[part 1 of 5: package /IBNvBlkSWC_4]
AUTOSAR XML (schema 00050)
package /IBNvBlkSWC_4
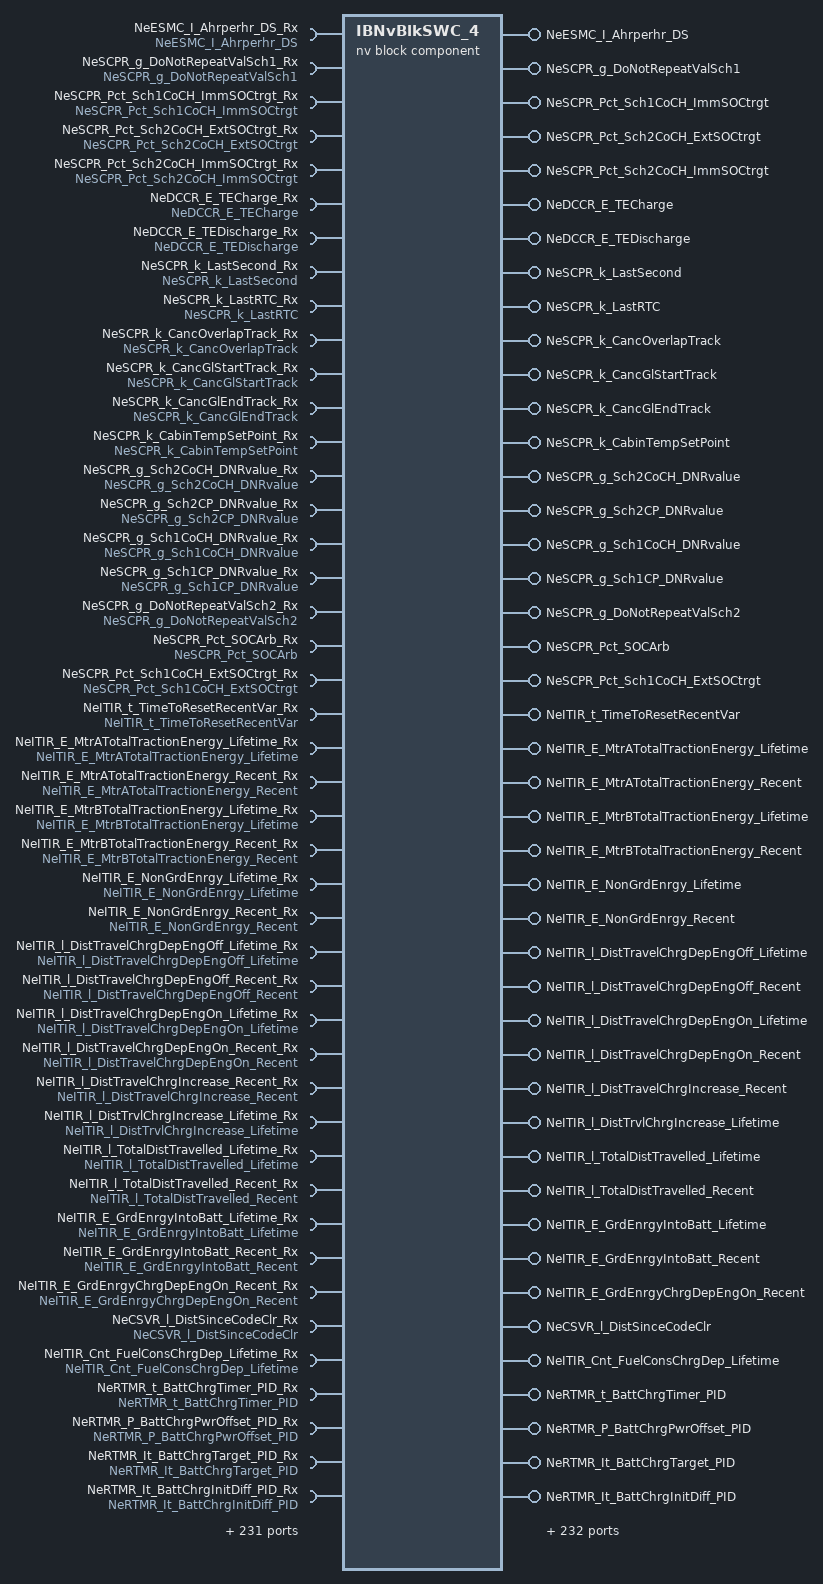
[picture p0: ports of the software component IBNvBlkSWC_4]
  nv block sw component type IBNvBlkSWC_4
    provide port NeESMC_I_Ahrperhr_DS: nv-provide-com-spec{ram-block-init-value=Value:0, rom-block-init-value=Value:0, variable=NeESMC_I_Ahrperhr_DS}, provided-interface=NeESMC_I_Ahrperhr_DS
    require port NeESMC_I_Ahrperhr_DS_Rx: nv-require-com-spec{init-value=Value:0, variable=NeESMC_I_Ahrperhr_DS}, required-interface=NeESMC_I_Ahrperhr_DS
    provide port NeSCPR_g_DoNotRepeatValSch1: nv-provide-com-spec{ram-block-init-value=Value:0, rom-block-init-value=Value:0, variable=NeSCPR_g_DoNotRepeatValSch1}, provided-interface=NeSCPR_g_DoNotRepeatValSch1
    require port NeSCPR_g_DoNotRepeatValSch1_Rx: nv-require-com-spec{init-value=Value:0, variable=NeSCPR_g_DoNotRepeatValSch1}, required-interface=NeSCPR_g_DoNotRepeatValSch1
    provide port NeSCPR_Pct_Sch1CoCH_ImmSOCtrgt: nv-provide-com-spec{ram-block-init-value=Value:0, rom-block-init-value=Value:0, variable=NeSCPR_Pct_Sch1CoCH_ImmSOCtrgt}, provided-interface=NeSCPR_Pct_Sch1CoCH_ImmSOCtrgt
    require port NeSCPR_Pct_Sch1CoCH_ImmSOCtrgt_Rx: nv-require-com-spec{init-value=Value:0, variable=NeSCPR_Pct_Sch1CoCH_ImmSOCtrgt}, required-interface=NeSCPR_Pct_Sch1CoCH_ImmSOCtrgt
    provide port NeSCPR_Pct_Sch2CoCH_ExtSOCtrgt: nv-provide-com-spec{ram-block-init-value=Value:0, rom-block-init-value=Value:0, variable=NeSCPR_Pct_Sch2CoCH_ExtSOCtrgt}, provided-interface=NeSCPR_Pct_Sch2CoCH_ExtSOCtrgt
    require port NeSCPR_Pct_Sch2CoCH_ExtSOCtrgt_Rx: nv-require-com-spec{init-value=Value:0, variable=NeSCPR_Pct_Sch2CoCH_ExtSOCtrgt}, required-interface=NeSCPR_Pct_Sch2CoCH_ExtSOCtrgt
    provide port NeSCPR_Pct_Sch2CoCH_ImmSOCtrgt: nv-provide-com-spec{ram-block-init-value=Value:0, rom-block-init-value=Value:0, variable=NeSCPR_Pct_Sch2CoCH_ImmSOCtrgt}, provided-interface=NeSCPR_Pct_Sch2CoCH_ImmSOCtrgt
    require port NeSCPR_Pct_Sch2CoCH_ImmSOCtrgt_Rx: nv-require-com-spec{init-value=Value:0, variable=NeSCPR_Pct_Sch2CoCH_ImmSOCtrgt}, required-interface=NeSCPR_Pct_Sch2CoCH_ImmSOCtrgt
    provide port NeDCCR_E_TECharge: nv-provide-com-spec{ram-block-init-value=Value:0, rom-block-init-value=Value:0, variable=NeDCCR_E_TECharge}, provided-interface=NeDCCR_E_TECharge
    require port NeDCCR_E_TECharge_Rx: nv-require-com-spec{init-value=Value:0, variable=NeDCCR_E_TECharge}, required-interface=NeDCCR_E_TECharge
    provide port NeDCCR_E_TEDischarge: nv-provide-com-spec{ram-block-init-value=Value:0, rom-block-init-value=Value:0, variable=NeDCCR_E_TEDischarge}, provided-interface=NeDCCR_E_TEDischarge
    require port NeDCCR_E_TEDischarge_Rx: nv-require-com-spec{init-value=Value:0, variable=NeDCCR_E_TEDischarge}, required-interface=NeDCCR_E_TEDischarge
    provide port NeSCPR_k_LastSecond: nv-provide-com-spec{ram-block-init-value=Value:0, rom-block-init-value=Value:0, variable=NeSCPR_k_LastSecond}, provided-interface=NeSCPR_k_LastSecond
    require port NeSCPR_k_LastSecond_Rx: nv-require-com-spec{init-value=Value:0, variable=NeSCPR_k_LastSecond}, required-interface=NeSCPR_k_LastSecond
    provide port NeSCPR_k_LastRTC: nv-provide-com-spec{ram-block-init-value=Value:0, rom-block-init-value=Value:0, variable=NeSCPR_k_LastRTC}, provided-interface=NeSCPR_k_LastRTC
    require port NeSCPR_k_LastRTC_Rx: nv-require-com-spec{init-value=Value:0, variable=NeSCPR_k_LastRTC}, required-interface=NeSCPR_k_LastRTC
    provide port NeSCPR_k_CancOverlapTrack: nv-provide-com-spec{ram-block-init-value=Value:0, rom-block-init-value=Value:0, variable=NeSCPR_k_CancOverlapTrack}, provided-interface=NeSCPR_k_CancOverlapTrack
    require port NeSCPR_k_CancOverlapTrack_Rx: nv-require-com-spec{init-value=Value:0, variable=NeSCPR_k_CancOverlapTrack}, required-interface=NeSCPR_k_CancOverlapTrack
    provide port NeSCPR_k_CancGlStartTrack: nv-provide-com-spec{ram-block-init-value=Value:0, rom-block-init-value=Value:0, variable=NeSCPR_k_CancGlStartTrack}, provided-interface=NeSCPR_k_CancGlStartTrack
    require port NeSCPR_k_CancGlStartTrack_Rx: nv-require-com-spec{init-value=Value:0, variable=NeSCPR_k_CancGlStartTrack}, required-interface=NeSCPR_k_CancGlStartTrack
    provide port NeSCPR_k_CancGlEndTrack: nv-provide-com-spec{ram-block-init-value=Value:0, rom-block-init-value=Value:0, variable=NeSCPR_k_CancGlEndTrack}, provided-interface=NeSCPR_k_CancGlEndTrack
    require port NeSCPR_k_CancGlEndTrack_Rx: nv-require-com-spec{init-value=Value:0, variable=NeSCPR_k_CancGlEndTrack}, required-interface=NeSCPR_k_CancGlEndTrack
    provide port NeSCPR_k_CabinTempSetPoint: nv-provide-com-spec{ram-block-init-value=Value:4294967295, rom-block-init-value=Value:4294967295, variable=NeSCPR_k_CabinTempSetPoint}, provided-interface=NeSCPR_k_CabinTempSetPoint
    require port NeSCPR_k_CabinTempSetPoint_Rx: nv-require-com-spec{init-value=Value:4294967295, variable=NeSCPR_k_CabinTempSetPoint}, required-interface=NeSCPR_k_CabinTempSetPoint
    provide port NeSCPR_g_Sch2CoCH_DNRvalue: nv-provide-com-spec{ram-block-init-value=Value:0, rom-block-init-value=Value:0, variable=NeSCPR_g_Sch2CoCH_DNRvalue}, provided-interface=NeSCPR_g_Sch2CoCH_DNRvalue
    require port NeSCPR_g_Sch2CoCH_DNRvalue_Rx: nv-require-com-spec{init-value=Value:0, variable=NeSCPR_g_Sch2CoCH_DNRvalue}, required-interface=NeSCPR_g_Sch2CoCH_DNRvalue
    provide port NeSCPR_g_Sch2CP_DNRvalue: nv-provide-com-spec{ram-block-init-value=Value:0, rom-block-init-value=Value:0, variable=NeSCPR_g_Sch2CP_DNRvalue}, provided-interface=NeSCPR_g_Sch2CP_DNRvalue
    require port NeSCPR_g_Sch2CP_DNRvalue_Rx: nv-require-com-spec{init-value=Value:0, variable=NeSCPR_g_Sch2CP_DNRvalue}, required-interface=NeSCPR_g_Sch2CP_DNRvalue
    provide port NeSCPR_g_Sch1CoCH_DNRvalue: nv-provide-com-spec{ram-block-init-value=Value:0, rom-block-init-value=Value:0, variable=NeSCPR_g_Sch1CoCH_DNRvalue}, provided-interface=NeSCPR_g_Sch1CoCH_DNRvalue
    require port NeSCPR_g_Sch1CoCH_DNRvalue_Rx: nv-require-com-spec{init-value=Value:0, variable=NeSCPR_g_Sch1CoCH_DNRvalue}, required-interface=NeSCPR_g_Sch1CoCH_DNRvalue
    provide port NeSCPR_g_Sch1CP_DNRvalue: nv-provide-com-spec{ram-block-init-value=Value:0, rom-block-init-value=Value:0, variable=NeSCPR_g_Sch1CP_DNRvalue}, provided-interface=NeSCPR_g_Sch1CP_DNRvalue
    require port NeSCPR_g_Sch1CP_DNRvalue_Rx: nv-require-com-spec{init-value=Value:0, variable=NeSCPR_g_Sch1CP_DNRvalue}, required-interface=NeSCPR_g_Sch1CP_DNRvalue
    provide port NeSCPR_g_DoNotRepeatValSch2: nv-provide-com-spec{ram-block-init-value=Value:0, rom-block-init-value=Value:0, variable=NeSCPR_g_DoNotRepeatValSch2}, provided-interface=NeSCPR_g_DoNotRepeatValSch2
    require port NeSCPR_g_DoNotRepeatValSch2_Rx: nv-require-com-spec{init-value=Value:0, variable=NeSCPR_g_DoNotRepeatValSch2}, required-interface=NeSCPR_g_DoNotRepeatValSch2
    provide port NeSCPR_Pct_SOCArb: nv-provide-com-spec{ram-block-init-value=Value:100, rom-block-init-value=Value:100, variable=NeSCPR_Pct_SOCArb}, provided-interface=NeSCPR_Pct_SOCArb
    require port NeSCPR_Pct_SOCArb_Rx: nv-require-com-spec{init-value=Value:100, variable=NeSCPR_Pct_SOCArb}, required-interface=NeSCPR_Pct_SOCArb
    provide port NeSCPR_Pct_Sch1CoCH_ExtSOCtrgt: nv-provide-com-spec{ram-block-init-value=Value:0, rom-block-init-value=Value:0, variable=NeSCPR_Pct_Sch1CoCH_ExtSOCtrgt}, provided-interface=NeSCPR_Pct_Sch1CoCH_ExtSOCtrgt
    require port NeSCPR_Pct_Sch1CoCH_ExtSOCtrgt_Rx: nv-require-com-spec{init-value=Value:0, variable=NeSCPR_Pct_Sch1CoCH_ExtSOCtrgt}, required-interface=NeSCPR_Pct_Sch1CoCH_ExtSOCtrgt
    provide port NeITIR_t_TimeToResetRecentVar: nv-provide-com-spec{ram-block-init-value=Value:0, rom-block-init-value=Value:0, variable=NeITIR_t_TimeToResetRecentVar}, provided-interface=NeITIR_t_TimeToResetRecentVar
    require port NeITIR_t_TimeToResetRecentVar_Rx: nv-require-com-spec{init-value=Value:0, variable=NeITIR_t_TimeToResetRecentVar}, required-interface=NeITIR_t_TimeToResetRecentVar
    provide port NeITIR_E_MtrATotalTractionEnergy_Lifetime: nv-provide-com-spec{ram-block-init-value=Value:0, rom-block-init-value=Value:0, variable=NeITIR_E_MtrATotalTractionEnergy_Lifetime}, provided-interface=NeITIR_E_MtrATotalTractionEnergy_Lifetime
    require port NeITIR_E_MtrATotalTractionEnergy_Lifetime_Rx: nv-require-com-spec{init-value=Value:0, variable=NeITIR_E_MtrATotalTractionEnergy_Lifetime}, required-interface=NeITIR_E_MtrATotalTractionEnergy_Lifetime
    provide port NeITIR_E_MtrATotalTractionEnergy_Recent: nv-provide-com-spec{ram-block-init-value=Value:0, rom-block-init-value=Value:0, variable=NeITIR_E_MtrATotalTractionEnergy_Recent}, provided-interface=NeITIR_E_MtrATotalTractionEnergy_Recent
    require port NeITIR_E_MtrATotalTractionEnergy_Recent_Rx: nv-require-com-spec{init-value=Value:0, variable=NeITIR_E_MtrATotalTractionEnergy_Recent}, required-interface=NeITIR_E_MtrATotalTractionEnergy_Recent
    provide port NeITIR_E_MtrBTotalTractionEnergy_Lifetime: nv-provide-com-spec{ram-block-init-value=Value:0, rom-block-init-value=Value:0, variable=NeITIR_E_MtrBTotalTractionEnergy_Lifetime}, provided-interface=NeITIR_E_MtrBTotalTractionEnergy_Lifetime
    require port NeITIR_E_MtrBTotalTractionEnergy_Lifetime_Rx: nv-require-com-spec{init-value=Value:0, variable=NeITIR_E_MtrBTotalTractionEnergy_Lifetime}, required-interface=NeITIR_E_MtrBTotalTractionEnergy_Lifetime
    provide port NeITIR_E_MtrBTotalTractionEnergy_Recent: nv-provide-com-spec{ram-block-init-value=Value:0, rom-block-init-value=Value:0, variable=NeITIR_E_MtrBTotalTractionEnergy_Recent}, provided-interface=NeITIR_E_MtrBTotalTractionEnergy_Recent
    require port NeITIR_E_MtrBTotalTractionEnergy_Recent_Rx: nv-require-com-spec{init-value=Value:0, variable=NeITIR_E_MtrBTotalTractionEnergy_Recent}, required-interface=NeITIR_E_MtrBTotalTractionEnergy_Recent
    provide port NeITIR_E_NonGrdEnrgy_Lifetime: nv-provide-com-spec{ram-block-init-value=Value:0, rom-block-init-value=Value:0, variable=NeITIR_E_NonGrdEnrgy_Lifetime}, provided-interface=NeITIR_E_NonGrdEnrgy_Lifetime
    require port NeITIR_E_NonGrdEnrgy_Lifetime_Rx: nv-require-com-spec{init-value=Value:0, variable=NeITIR_E_NonGrdEnrgy_Lifetime}, required-interface=NeITIR_E_NonGrdEnrgy_Lifetime
    provide port NeITIR_E_NonGrdEnrgy_Recent: nv-provide-com-spec{ram-block-init-value=Value:0, rom-block-init-value=Value:0, variable=NeITIR_E_NonGrdEnrgy_Recent}, provided-interface=NeITIR_E_NonGrdEnrgy_Recent
    require port NeITIR_E_NonGrdEnrgy_Recent_Rx: nv-require-com-spec{init-value=Value:0, variable=NeITIR_E_NonGrdEnrgy_Recent}, required-interface=NeITIR_E_NonGrdEnrgy_Recent
    provide port NeITIR_l_DistTravelChrgDepEngOff_Lifetime: nv-provide-com-spec{ram-block-init-value=Value:0, rom-block-init-value=Value:0, variable=NeITIR_l_DistTravelChrgDepEngOff_Lifetime}, provided-interface=NeITIR_l_DistTravelChrgDepEngOff_Lifetime
    require port NeITIR_l_DistTravelChrgDepEngOff_Lifetime_Rx: nv-require-com-spec{init-value=Value:0, variable=NeITIR_l_DistTravelChrgDepEngOff_Lifetime}, required-interface=NeITIR_l_DistTravelChrgDepEngOff_Lifetime
    provide port NeITIR_l_DistTravelChrgDepEngOff_Recent: nv-provide-com-spec{ram-block-init-value=Value:0, rom-block-init-value=Value:0, variable=NeITIR_l_DistTravelChrgDepEngOff_Recent}, provided-interface=NeITIR_l_DistTravelChrgDepEngOff_Recent
    require port NeITIR_l_DistTravelChrgDepEngOff_Recent_Rx: nv-require-com-spec{init-value=Value:0, variable=NeITIR_l_DistTravelChrgDepEngOff_Recent}, required-interface=NeITIR_l_DistTravelChrgDepEngOff_Recent
    provide port NeITIR_l_DistTravelChrgDepEngOn_Lifetime: nv-provide-com-spec{ram-block-init-value=Value:0, rom-block-init-value=Value:0, variable=NeITIR_l_DistTravelChrgDepEngOn_Lifetime}, provided-interface=NeITIR_l_DistTravelChrgDepEngOn_Lifetime
    require port NeITIR_l_DistTravelChrgDepEngOn_Lifetime_Rx: nv-require-com-spec{init-value=Value:0, variable=NeITIR_l_DistTravelChrgDepEngOn_Lifetime}, required-interface=NeITIR_l_DistTravelChrgDepEngOn_Lifetime
    provide port NeITIR_l_DistTravelChrgDepEngOn_Recent: nv-provide-com-spec{ram-block-init-value=Value:0, rom-block-init-value=Value:0, variable=NeITIR_l_DistTravelChrgDepEngOn_Recent}, provided-interface=NeITIR_l_DistTravelChrgDepEngOn_Recent
    require port NeITIR_l_DistTravelChrgDepEngOn_Recent_Rx: nv-require-com-spec{init-value=Value:0, variable=NeITIR_l_DistTravelChrgDepEngOn_Recent}, required-interface=NeITIR_l_DistTravelChrgDepEngOn_Recent
    provide port NeITIR_l_DistTravelChrgIncrease_Recent: nv-provide-com-spec{ram-block-init-value=Value:0, rom-block-init-value=Value:0, variable=NeITIR_l_DistTravelChrgIncrease_Recent}, provided-interface=NeITIR_l_DistTravelChrgIncrease_Recent
    require port NeITIR_l_DistTravelChrgIncrease_Recent_Rx: nv-require-com-spec{init-value=Value:0, variable=NeITIR_l_DistTravelChrgIncrease_Recent}, required-interface=NeITIR_l_DistTravelChrgIncrease_Recent
    provide port NeITIR_l_DistTrvlChrgIncrease_Lifetime: nv-provide-com-spec{ram-block-init-value=Value:0, rom-block-init-value=Value:0, variable=NeITIR_l_DistTrvlChrgIncrease_Lifetime}, provided-interface=NeITIR_l_DistTrvlChrgIncrease_Lifetime
    require port NeITIR_l_DistTrvlChrgIncrease_Lifetime_Rx: nv-require-com-spec{init-value=Value:0, variable=NeITIR_l_DistTrvlChrgIncrease_Lifetime}, required-interface=NeITIR_l_DistTrvlChrgIncrease_Lifetime
    provide port NeITIR_l_TotalDistTravelled_Lifetime: nv-provide-com-spec{ram-block-init-value=Value:0, rom-block-init-value=Value:0, variable=NeITIR_l_TotalDistTravelled_Lifetime}, provided-interface=NeITIR_l_TotalDistTravelled_Lifetime
    require port NeITIR_l_TotalDistTravelled_Lifetime_Rx: nv-require-com-spec{init-value=Value:0, variable=NeITIR_l_TotalDistTravelled_Lifetime}, required-interface=NeITIR_l_TotalDistTravelled_Lifetime
    provide port NeITIR_l_TotalDistTravelled_Recent: nv-provide-com-spec{ram-block-init-value=Value:0, rom-block-init-value=Value:0, variable=NeITIR_l_TotalDistTravelled_Recent}, provided-interface=NeITIR_l_TotalDistTravelled_Recent
    require port NeITIR_l_TotalDistTravelled_Recent_Rx: nv-require-com-spec{init-value=Value:0, variable=NeITIR_l_TotalDistTravelled_Recent}, required-interface=NeITIR_l_TotalDistTravelled_Recent
    provide port NeITIR_E_GrdEnrgyIntoBatt_Lifetime: nv-provide-com-spec{ram-block-init-value=Value:0, rom-block-init-value=Value:0, variable=NeITIR_E_GrdEnrgyIntoBatt_Lifetime}, provided-interface=NeITIR_E_GrdEnrgyIntoBatt_Lifetime
    require port NeITIR_E_GrdEnrgyIntoBatt_Lifetime_Rx: nv-require-com-spec{init-value=Value:0, variable=NeITIR_E_GrdEnrgyIntoBatt_Lifetime}, required-interface=NeITIR_E_GrdEnrgyIntoBatt_Lifetime
    provide port NeITIR_E_GrdEnrgyIntoBatt_Recent: nv-provide-com-spec{ram-block-init-value=Value:0, rom-block-init-value=Value:0, variable=NeITIR_E_GrdEnrgyIntoBatt_Recent}, provided-interface=NeITIR_E_GrdEnrgyIntoBatt_Recent
    require port NeITIR_E_GrdEnrgyIntoBatt_Recent_Rx: nv-require-com-spec{init-value=Value:0, variable=NeITIR_E_GrdEnrgyIntoBatt_Recent}, required-interface=NeITIR_E_GrdEnrgyIntoBatt_Recent
    provide port NeITIR_E_GrdEnrgyChrgDepEngOn_Recent: nv-provide-com-spec{ram-block-init-value=Value:0, rom-block-init-value=Value:0, variable=NeITIR_E_GrdEnrgyChrgDepEngOn_Recent}, provided-interface=NeITIR_E_GrdEnrgyChrgDepEngOn_Recent
    require port NeITIR_E_GrdEnrgyChrgDepEngOn_Recent_Rx: nv-require-com-spec{init-value=Value:0, variable=NeITIR_E_GrdEnrgyChrgDepEngOn_Recent}, required-interface=NeITIR_E_GrdEnrgyChrgDepEngOn_Recent
    provide port NeCSVR_l_DistSinceCodeClr: nv-provide-com-spec{ram-block-init-value=Value:0, rom-block-init-value=Value:0, variable=NeCSVR_l_DistSinceCodeClr}, provided-interface=NeCSVR_l_DistSinceCodeClr
    require port NeCSVR_l_DistSinceCodeClr_Rx: nv-require-com-spec{init-value=Value:0, variable=NeCSVR_l_DistSinceCodeClr}, required-interface=NeCSVR_l_DistSinceCodeClr
    provide port NeITIR_Cnt_FuelConsChrgDep_Lifetime: nv-provide-com-spec{ram-block-init-value=Value:0, rom-block-init-value=Value:0, variable=NeITIR_Cnt_FuelConsChrgDep_Lifetime}, provided-interface=NeITIR_Cnt_FuelConsChrgDep_Lifetime
    require port NeITIR_Cnt_FuelConsChrgDep_Lifetime_Rx: nv-require-com-spec{init-value=Value:0, variable=NeITIR_Cnt_FuelConsChrgDep_Lifetime}, required-interface=NeITIR_Cnt_FuelConsChrgDep_Lifetime
    provide port NeRTMR_t_BattChrgTimer_PID: nv-provide-com-spec{ram-block-init-value=Value:0, rom-block-init-value=Value:0, variable=NeRTMR_t_BattChrgTimer_PID}, provided-interface=NeRTMR_t_BattChrgTimer_PID
    require port NeRTMR_t_BattChrgTimer_PID_Rx: nv-require-com-spec{init-value=Value:0, variable=NeRTMR_t_BattChrgTimer_PID}, required-interface=NeRTMR_t_BattChrgTimer_PID
    provide port NeRTMR_P_BattChrgPwrOffset_PID: nv-provide-com-spec{ram-block-init-value=Value:0, rom-block-init-value=Value:0, variable=NeRTMR_P_BattChrgPwrOffset_PID}, provided-interface=NeRTMR_P_BattChrgPwrOffset_PID
    require port NeRTMR_P_BattChrgPwrOffset_PID_Rx: nv-require-com-spec{init-value=Value:0, variable=NeRTMR_P_BattChrgPwrOffset_PID}, required-interface=NeRTMR_P_BattChrgPwrOffset_PID
    provide port NeRTMR_It_BattChrgTarget_PID: nv-provide-com-spec{ram-block-init-value=Value:0, rom-block-init-value=Value:0, variable=NeRTMR_It_BattChrgTarget_PID}, provided-interface=NeRTMR_It_BattChrgTarget_PID
    require port NeRTMR_It_BattChrgTarget_PID_Rx: nv-require-com-spec{init-value=Value:0, variable=NeRTMR_It_BattChrgTarget_PID}, required-interface=NeRTMR_It_BattChrgTarget_PID
    provide port NeRTMR_It_BattChrgInitDiff_PID: nv-provide-com-spec{ram-block-init-value=Value:0, rom-block-init-value=Value:0, variable=NeRTMR_It_BattChrgInitDiff_PID}, provided-interface=NeRTMR_It_BattChrgInitDiff_PID
    require port NeRTMR_It_BattChrgInitDiff_PID_Rx: nv-require-com-spec{init-value=Value:0, variable=NeRTMR_It_BattChrgInitDiff_PID}, required-interface=NeRTMR_It_BattChrgInitDiff_PID
    provide port NeRTMR_It_BattChargedAmnt_PID: nv-provide-com-spec{ram-block-init-value=Value:0, rom-block-init-value=Value:0, variable=NeRTMR_It_BattChargedAmnt_PID}, provided-interface=NeRTMR_It_BattChargedAmnt_PID
    require port NeRTMR_It_BattChargedAmnt_PID_Rx: nv-require-com-spec{init-value=Value:0, variable=NeRTMR_It_BattChargedAmnt_PID}, required-interface=NeRTMR_It_BattChargedAmnt_PID
    provide port NeITIR_Cnt_FuelConsChrgDep_Recent: nv-provide-com-spec{ram-block-init-value=Value:0, rom-block-init-value=Value:0, variable=NeITIR_Cnt_FuelConsChrgDep_Recent}, provided-interface=NeITIR_Cnt_FuelConsChrgDep_Recent
    require port NeITIR_Cnt_FuelConsChrgDep_Recent_Rx: nv-require-com-spec{init-value=Value:0, variable=NeITIR_Cnt_FuelConsChrgDep_Recent}, required-interface=NeITIR_Cnt_FuelConsChrgDep_Recent
    provide port NeITIR_E_GrdEnrgyChrgDepEngOn_Lifetime: nv-provide-com-spec{ram-block-init-value=Value:0, rom-block-init-value=Value:0, variable=NeITIR_E_GrdEnrgyChrgDepEngOn_Lifetime}, provided-interface=NeITIR_E_GrdEnrgyChrgDepEngOn_Lifetime
    require port NeITIR_E_GrdEnrgyChrgDepEngOn_Lifetime_Rx: nv-require-com-spec{init-value=Value:0, variable=NeITIR_E_GrdEnrgyChrgDepEngOn_Lifetime}, required-interface=NeITIR_E_GrdEnrgyChrgDepEngOn_Lifetime
    provide port NeITIR_Cnt_FuelConsChrgIncrease_Lifetime: nv-provide-com-spec{ram-block-init-value=Value:0, rom-block-init-value=Value:0, variable=NeITIR_Cnt_FuelConsChrgIncrease_Lifetime}, provided-interface=NeITIR_Cnt_FuelConsChrgIncrease_Lifetime
    require port NeITIR_Cnt_FuelConsChrgIncrease_Lifetime_Rx: nv-require-com-spec{init-value=Value:0, variable=NeITIR_Cnt_FuelConsChrgIncrease_Lifetime}, required-interface=NeITIR_Cnt_FuelConsChrgIncrease_Lifetime
    provide port NeITIR_Cnt_FuelConsChrgIncrease_Recent: nv-provide-com-spec{ram-block-init-value=Value:0, rom-block-init-value=Value:0, variable=NeITIR_Cnt_FuelConsChrgIncrease_Recent}, provided-interface=NeITIR_Cnt_FuelConsChrgIncrease_Recent
    require port NeITIR_Cnt_FuelConsChrgIncrease_Recent_Rx: nv-require-com-spec{init-value=Value:0, variable=NeITIR_Cnt_FuelConsChrgIncrease_Recent}, required-interface=NeITIR_Cnt_FuelConsChrgIncrease_Recent
    provide port NeITIR_Cnt_FuelEngIgnCycl_Lifetime: nv-provide-com-spec{ram-block-init-value=Value:0, rom-block-init-value=Value:0, variable=NeITIR_Cnt_FuelEngIgnCycl_Lifetime}, provided-interface=NeITIR_Cnt_FuelEngIgnCycl_Lifetime
    require port NeITIR_Cnt_FuelEngIgnCycl_Lifetime_Rx: nv-require-com-spec{init-value=Value:0, variable=NeITIR_Cnt_FuelEngIgnCycl_Lifetime}, required-interface=NeITIR_Cnt_FuelEngIgnCycl_Lifetime
    provide port NeITIR_Cnt_FuelEngIgnCycl_Recent: nv-provide-com-spec{ram-block-init-value=Value:0, rom-block-init-value=Value:0, variable=NeITIR_Cnt_FuelEngIgnCycl_Recent}, provided-interface=NeITIR_Cnt_FuelEngIgnCycl_Recent
    require port NeITIR_Cnt_FuelEngIgnCycl_Recent_Rx: nv-require-com-spec{init-value=Value:0, variable=NeITIR_Cnt_FuelEngIgnCycl_Recent}, required-interface=NeITIR_Cnt_FuelEngIgnCycl_Recent
    provide port NeITIR_Cnt_IgnCycl_Lifetime: nv-provide-com-spec{ram-block-init-value=Value:0, rom-block-init-value=Value:0, variable=NeITIR_Cnt_IgnCycl_Lifetime}, provided-interface=NeITIR_Cnt_IgnCycl_Lifetime
    require port NeITIR_Cnt_IgnCycl_Lifetime_Rx: nv-require-com-spec{init-value=Value:0, variable=NeITIR_Cnt_IgnCycl_Lifetime}, required-interface=NeITIR_Cnt_IgnCycl_Lifetime
    provide port NeITIR_Cnt_IgnCycl_Recent: nv-provide-com-spec{ram-block-init-value=Value:0, rom-block-init-value=Value:0, variable=NeITIR_Cnt_IgnCycl_Recent}, provided-interface=NeITIR_Cnt_IgnCycl_Recent
    require port NeITIR_Cnt_IgnCycl_Recent_Rx: nv-require-com-spec{init-value=Value:0, variable=NeITIR_Cnt_IgnCycl_Recent}, required-interface=NeITIR_Cnt_IgnCycl_Recent
    provide port NeITIR_Cnt_Total_City_PSA_Time_Lifetime: nv-provide-com-spec{ram-block-init-value=Value:0, rom-block-init-value=Value:0, variable=NeITIR_Cnt_Total_City_PSA_Time_Lifetime}, provided-interface=NeITIR_Cnt_Total_City_PSA_Time_Lifetime
    require port NeITIR_Cnt_Total_City_PSA_Time_Lifetime_Rx: nv-require-com-spec{init-value=Value:0, variable=NeITIR_Cnt_Total_City_PSA_Time_Lifetime}, required-interface=NeITIR_Cnt_Total_City_PSA_Time_Lifetime
    provide port NeITIR_Cnt_Total_City_PSA_Time_Recent: nv-provide-com-spec{ram-block-init-value=Value:0, rom-block-init-value=Value:0, variable=NeITIR_Cnt_Total_City_PSA_Time_Recent}, provided-interface=NeITIR_Cnt_Total_City_PSA_Time_Recent
    require port NeITIR_Cnt_Total_City_PSA_Time_Recent_Rx: nv-require-com-spec{init-value=Value:0, variable=NeITIR_Cnt_Total_City_PSA_Time_Recent}, required-interface=NeITIR_Cnt_Total_City_PSA_Time_Recent
    provide port NeITIR_Cnt_Total_Idle_PSA_Time_Lifetime: nv-provide-com-spec{ram-block-init-value=Value:0, rom-block-init-value=Value:0, variable=NeITIR_Cnt_Total_Idle_PSA_Time_Lifetime}, provided-interface=NeITIR_Cnt_Total_Idle_PSA_Time_Lifetime
    require port NeITIR_Cnt_Total_Idle_PSA_Time_Lifetime_Rx: nv-require-com-spec{init-value=Value:0, variable=NeITIR_Cnt_Total_Idle_PSA_Time_Lifetime}, required-interface=NeITIR_Cnt_Total_Idle_PSA_Time_Lifetime
    provide port NeITIR_Cnt_Total_Idle_PSA_Time_Recent: nv-provide-com-spec{ram-block-init-value=Value:0, rom-block-init-value=Value:0, variable=NeITIR_Cnt_Total_Idle_PSA_Time_Recent}, provided-interface=NeITIR_Cnt_Total_Idle_PSA_Time_Recent
    require port NeITIR_Cnt_Total_Idle_PSA_Time_Recent_Rx: nv-require-com-spec{init-value=Value:0, variable=NeITIR_Cnt_Total_Idle_PSA_Time_Recent}, required-interface=NeITIR_Cnt_Total_Idle_PSA_Time_Recent
    provide port NeITIR_Cnt_Total_PSA_Time_Lifetime: nv-provide-com-spec{ram-block-init-value=Value:0, rom-block-init-value=Value:0, variable=NeITIR_Cnt_Total_PSA_Time_Lifetime}, provided-interface=NeITIR_Cnt_Total_PSA_Time_Lifetime
    require port NeITIR_Cnt_Total_PSA_Time_Lifetime_Rx: nv-require-com-spec{init-value=Value:0, variable=NeITIR_Cnt_Total_PSA_Time_Lifetime}, required-interface=NeITIR_Cnt_Total_PSA_Time_Lifetime
    provide port NeITIR_Cnt_Total_PSA_Time_Recent: nv-provide-com-spec{ram-block-init-value=Value:0, rom-block-init-value=Value:0, variable=NeITIR_Cnt_Total_PSA_Time_Recent}, provided-interface=NeITIR_Cnt_Total_PSA_Time_Recent
    require port NeITIR_Cnt_Total_PSA_Time_Recent_Rx: nv-require-com-spec{init-value=Value:0, variable=NeITIR_Cnt_Total_PSA_Time_Recent}, required-interface=NeITIR_Cnt_Total_PSA_Time_Recent
    provide port NeITIR_E_GrdEnrgyChrgDepEngOff_Lifetime: nv-provide-com-spec{ram-block-init-value=Value:0, rom-block-init-value=Value:0, variable=NeITIR_E_GrdEnrgyChrgDepEngOff_Lifetime}, provided-interface=NeITIR_E_GrdEnrgyChrgDepEngOff_Lifetime
    require port NeITIR_E_GrdEnrgyChrgDepEngOff_Lifetime_Rx: nv-require-com-spec{init-value=Value:0, variable=NeITIR_E_GrdEnrgyChrgDepEngOff_Lifetime}, required-interface=NeITIR_E_GrdEnrgyChrgDepEngOff_Lifetime
    provide port NeITIR_E_GrdEnrgyChrgDepEngOff_Recent: nv-provide-com-spec{ram-block-init-value=Value:0, rom-block-init-value=Value:0, variable=NeITIR_E_GrdEnrgyChrgDepEngOff_Recent}, provided-interface=NeITIR_E_GrdEnrgyChrgDepEngOff_Recent
    require port NeITIR_E_GrdEnrgyChrgDepEngOff_Recent_Rx: nv-require-com-spec{init-value=Value:0, variable=NeITIR_E_GrdEnrgyChrgDepEngOff_Recent}, required-interface=NeITIR_E_GrdEnrgyChrgDepEngOff_Recent
    provide port NeCSVR_l_DistTravelMIL_On: nv-provide-com-spec{ram-block-init-value=Value:0, rom-block-init-value=Value:0, variable=NeCSVR_l_DistTravelMIL_On}, provided-interface=NeCSVR_l_DistTravelMIL_On
    require port NeCSVR_l_DistTravelMIL_On_Rx: nv-require-com-spec{init-value=Value:0, variable=NeCSVR_l_DistTravelMIL_On}, required-interface=NeCSVR_l_DistTravelMIL_On
    provide port NeBPCR_T_BatModTmp: nv-provide-com-spec{ram-block-init-value=Value:0, rom-block-init-value=Value:0, variable=NeBPCR_T_BatModTmp}, provided-interface=NeBPCR_T_BatModTmp
    require port NeBPCR_T_BatModTmp_Rx: nv-require-com-spec{init-value=Value:0, variable=NeBPCR_T_BatModTmp}, required-interface=NeBPCR_T_BatModTmp
    provide port NeTPCR_Pct_WupSOC: nv-provide-com-spec{ram-block-init-value=Value:4294967295, rom-block-init-value=Value:4294967295, variable=NeTPCR_Pct_WupSOC}, provided-interface=NeTPCR_Pct_WupSOC
    require port NeTPCR_Pct_WupSOC_Rx: nv-require-com-spec{init-value=Value:4294967295, variable=NeTPCR_Pct_WupSOC}, required-interface=NeTPCR_Pct_WupSOC
    provide port NeCCCR_P_PLSMaxPower: nv-provide-com-spec{ram-block-init-value=Value:0, rom-block-init-value=Value:0, variable=NeCCCR_P_PLSMaxPower}, provided-interface=NeCCCR_P_PLSMaxPower
    require port NeCCCR_P_PLSMaxPower_Rx: nv-require-com-spec{init-value=Value:0, variable=NeCCCR_P_PLSMaxPower}, required-interface=NeCCCR_P_PLSMaxPower
    provide port NeCCCR_T_AmbTemp_CntrlrOff: nv-provide-com-spec{ram-block-init-value=Value:0, rom-block-init-value=Value:0, variable=NeCCCR_T_AmbTemp_CntrlrOff}, provided-interface=NeCCCR_T_AmbTemp_CntrlrOff
    require port NeCCCR_T_AmbTemp_CntrlrOff_Rx: nv-require-com-spec{init-value=Value:0, variable=NeCCCR_T_AmbTemp_CntrlrOff}, required-interface=NeCCCR_T_AmbTemp_CntrlrOff
    provide port NeCCCR_T_EngTemp_CntrlrOff: nv-provide-com-spec{ram-block-init-value=Value:0, rom-block-init-value=Value:0, variable=NeCCCR_T_EngTemp_CntrlrOff}, provided-interface=NeCCCR_T_EngTemp_CntrlrOff
    require port NeCCCR_T_EngTemp_CntrlrOff_Rx: nv-require-com-spec{init-value=Value:0, variable=NeCCCR_T_EngTemp_CntrlrOff}, required-interface=NeCCCR_T_EngTemp_CntrlrOff
    provide port NeCCCR_t_CntrlrOnTime: nv-provide-com-spec{ram-block-init-value=Value:0, rom-block-init-value=Value:0, variable=NeCCCR_t_CntrlrOnTime}, provided-interface=NeCCCR_t_CntrlrOnTime
    require port NeCCCR_t_CntrlrOnTime_Rx: nv-require-com-spec{init-value=Value:0, variable=NeCCCR_t_CntrlrOnTime}, required-interface=NeCCCR_t_CntrlrOnTime
    provide port NeASLR_v_InitVehSpdLim: nv-provide-com-spec{ram-block-init-value=Value:0, rom-block-init-value=Value:0, variable=NeASLR_v_InitVehSpdLim}, provided-interface=NeASLR_v_InitVehSpdLim
    require port NeASLR_v_InitVehSpdLim_Rx: nv-require-com-spec{init-value=Value:0, variable=NeASLR_v_InitVehSpdLim}, required-interface=NeASLR_v_InitVehSpdLim
    provide port NeAATR_T_AmbAirTempPred_Prev: nv-provide-com-spec{ram-block-init-value=Value:25, rom-block-init-value=Value:25, variable=NeAATR_T_AmbAirTempPred_Prev}, provided-interface=NeAATR_T_AmbAirTempPred_Prev
    require port NeAATR_T_AmbAirTempPred_Prev_Rx: nv-require-com-spec{init-value=Value:25, variable=NeAATR_T_AmbAirTempPred_Prev}, required-interface=NeAATR_T_AmbAirTempPred_Prev
    provide port NeCCCR_t_CntrlrOffTime: nv-provide-com-spec{ram-block-init-value=Value:0, rom-block-init-value=Value:0, variable=NeCCCR_t_CntrlrOffTime}, provided-interface=NeCCCR_t_CntrlrOffTime
    require port NeCCCR_t_CntrlrOffTime_Rx: nv-require-com-spec{init-value=Value:0, variable=NeCCCR_t_CntrlrOffTime}, required-interface=NeCCCR_t_CntrlrOffTime
    provide port NePWDR_Cnt_HVFuseEMFOP: nv-provide-com-spec{ram-block-init-value=Value:0, rom-block-init-value=Value:0, variable=NePWDR_Cnt_HVFuseEMFOP}, provided-interface=NePWDR_Cnt_HVFuseEMFOP
    require port NePWDR_Cnt_HVFuseEMFOP_Rx: nv-require-com-spec{init-value=Value:0, variable=NePWDR_Cnt_HVFuseEMFOP}, required-interface=NePWDR_Cnt_HVFuseEMFOP
    provide port NeVLDR_Cnt_CPV2_PerfDiag_MFOP: nv-provide-com-spec{ram-block-init-value=Value:0, rom-block-init-value=Value:0, variable=NeVLDR_Cnt_CPV2_PerfDiag_MFOP}, provided-interface=NeVLDR_Cnt_CPV2_PerfDiag_MFOP
    require port NeVLDR_Cnt_CPV2_PerfDiag_MFOP_Rx: nv-require-com-spec{init-value=Value:0, variable=NeVLDR_Cnt_CPV2_PerfDiag_MFOP}, required-interface=NeVLDR_Cnt_CPV2_PerfDiag_MFOP
    provide port NeVLDR_Cnt_BHV_PerfDiag_MFOP: nv-provide-com-spec{ram-block-init-value=Value:0, rom-block-init-value=Value:0, variable=NeVLDR_Cnt_BHV_PerfDiag_MFOP}, provided-interface=NeVLDR_Cnt_BHV_PerfDiag_MFOP
    require port NeVLDR_Cnt_BHV_PerfDiag_MFOP_Rx: nv-require-com-spec{init-value=Value:0, variable=NeVLDR_Cnt_BHV_PerfDiag_MFOP}, required-interface=NeVLDR_Cnt_BHV_PerfDiag_MFOP
    provide port NeVLDR_Cnt_CPV_PerfDiag_MFOP: nv-provide-com-spec{ram-block-init-value=Value:0, rom-block-init-value=Value:0, variable=NeVLDR_Cnt_CPV_PerfDiag_MFOP}, provided-interface=NeVLDR_Cnt_CPV_PerfDiag_MFOP
    require port NeVLDR_Cnt_CPV_PerfDiag_MFOP_Rx: nv-require-com-spec{init-value=Value:0, variable=NeVLDR_Cnt_CPV_PerfDiag_MFOP}, required-interface=NeVLDR_Cnt_CPV_PerfDiag_MFOP
    provide port NePWDR_Cnt_HVOverVoltFailureMSOF: nv-provide-com-spec{ram-block-init-value=Value:65535, rom-block-init-value=Value:65535, variable=NePWDR_Cnt_HVOverVoltFailureMSOF}, provided-interface=NePWDR_Cnt_HVOverVoltFailureMSOF
    require port NePWDR_Cnt_HVOverVoltFailureMSOF_Rx: nv-require-com-spec{init-value=Value:65535, variable=NePWDR_Cnt_HVOverVoltFailureMSOF}, required-interface=NePWDR_Cnt_HVOverVoltFailureMSOF
    provide port NeVLDR_Cnt_CabVlvOpeng_Err_MFOP: nv-provide-com-spec{ram-block-init-value=Value:0, rom-block-init-value=Value:0, variable=NeVLDR_Cnt_CabVlvOpeng_Err_MFOP}, provided-interface=NeVLDR_Cnt_CabVlvOpeng_Err_MFOP
    require port NeVLDR_Cnt_CabVlvOpeng_Err_MFOP_Rx: nv-require-com-spec{init-value=Value:0, variable=NeVLDR_Cnt_CabVlvOpeng_Err_MFOP}, required-interface=NeVLDR_Cnt_CabVlvOpeng_Err_MFOP
    provide port NePWDR_Cnt_HVOverVoltWarnMFOP: nv-provide-com-spec{ram-block-init-value=Value:0, rom-block-init-value=Value:0, variable=NePWDR_Cnt_HVOverVoltWarnMFOP}, provided-interface=NePWDR_Cnt_HVOverVoltWarnMFOP
    require port NePWDR_Cnt_HVOverVoltWarnMFOP_Rx: nv-require-com-spec{init-value=Value:0, variable=NePWDR_Cnt_HVOverVoltWarnMFOP}, required-interface=NePWDR_Cnt_HVOverVoltWarnMFOP
    provide port NeVLDR_Cnt_EEXV_PerfDiag_MFOP: nv-provide-com-spec{ram-block-init-value=Value:0, rom-block-init-value=Value:0, variable=NeVLDR_Cnt_EEXV_PerfDiag_MFOP}, provided-interface=NeVLDR_Cnt_EEXV_PerfDiag_MFOP
    require port NeVLDR_Cnt_EEXV_PerfDiag_MFOP_Rx: nv-require-com-spec{init-value=Value:0, variable=NeVLDR_Cnt_EEXV_PerfDiag_MFOP}, required-interface=NeVLDR_Cnt_EEXV_PerfDiag_MFOP
    provide port NeVLDR_Cnt_EEXV_PressElctrFlt_MFOP: nv-provide-com-spec{ram-block-init-value=Value:0, rom-block-init-value=Value:0, variable=NeVLDR_Cnt_EEXV_PressElctrFlt_MFOP}, provided-interface=NeVLDR_Cnt_EEXV_PressElctrFlt_MFOP
    require port NeVLDR_Cnt_EEXV_PressElctrFlt_MFOP_Rx: nv-require-com-spec{init-value=Value:0, variable=NeVLDR_Cnt_EEXV_PressElctrFlt_MFOP}, required-interface=NeVLDR_Cnt_EEXV_PressElctrFlt_MFOP
    provide port NePWDR_Cnt_HVFuseDMFOP: nv-provide-com-spec{ram-block-init-value=Value:0, rom-block-init-value=Value:0, variable=NePWDR_Cnt_HVFuseDMFOP}, provided-interface=NePWDR_Cnt_HVFuseDMFOP
    require port NePWDR_Cnt_HVFuseDMFOP_Rx: nv-require-com-spec{init-value=Value:0, variable=NePWDR_Cnt_HVFuseDMFOP}, required-interface=NePWDR_Cnt_HVFuseDMFOP
    provide port NePWDR_Cnt_HVFuseCMFOP: nv-provide-com-spec{ram-block-init-value=Value:0, rom-block-init-value=Value:0, variable=NePWDR_Cnt_HVFuseCMFOP}, provided-interface=NePWDR_Cnt_HVFuseCMFOP
    require port NePWDR_Cnt_HVFuseCMFOP_Rx: nv-require-com-spec{init-value=Value:0, variable=NePWDR_Cnt_HVFuseCMFOP}, required-interface=NePWDR_Cnt_HVFuseCMFOP
    provide port NePWDR_Cnt_HVILCkt_MFOP: nv-provide-com-spec{ram-block-init-value=Value:0, rom-block-init-value=Value:0, variable=NePWDR_Cnt_HVILCkt_MFOP}, provided-interface=NePWDR_Cnt_HVILCkt_MFOP
    require port NePWDR_Cnt_HVILCkt_MFOP_Rx: nv-require-com-spec{init-value=Value:0, variable=NePWDR_Cnt_HVILCkt_MFOP}, required-interface=NePWDR_Cnt_HVILCkt_MFOP
    provide port NePWDR_Cnt_HVFuseBMFOP: nv-provide-com-spec{ram-block-init-value=Value:0, rom-block-init-value=Value:0, variable=NePWDR_Cnt_HVFuseBMFOP}, provided-interface=NePWDR_Cnt_HVFuseBMFOP
    require port NePWDR_Cnt_HVFuseBMFOP_Rx: nv-require-com-spec{init-value=Value:0, variable=NePWDR_Cnt_HVFuseBMFOP}, required-interface=NePWDR_Cnt_HVFuseBMFOP
    provide port NePWDR_Cnt_HVFuseAMFOP: nv-provide-com-spec{ram-block-init-value=Value:0, rom-block-init-value=Value:0, variable=NePWDR_Cnt_HVFuseAMFOP}, provided-interface=NePWDR_Cnt_HVFuseAMFOP
    require port NePWDR_Cnt_HVFuseAMFOP_Rx: nv-require-com-spec{init-value=Value:0, variable=NePWDR_Cnt_HVFuseAMFOP}, required-interface=NePWDR_Cnt_HVFuseAMFOP
    provide port NePWDR_Cnt_HVDAPMFOP: nv-provide-com-spec{ram-block-init-value=Value:0, rom-block-init-value=Value:0, variable=NePWDR_Cnt_HVDAPMFOP}, provided-interface=NePWDR_Cnt_HVDAPMFOP
    require port NePWDR_Cnt_HVDAPMFOP_Rx: nv-require-com-spec{init-value=Value:0, variable=NePWDR_Cnt_HVDAPMFOP}, required-interface=NePWDR_Cnt_HVDAPMFOP
    provide port NePWDR_Cnt_HVOverVoltFailureMFOP: nv-provide-com-spec{ram-block-init-value=Value:0, rom-block-init-value=Value:0, variable=NePWDR_Cnt_HVOverVoltFailureMFOP}, provided-interface=NePWDR_Cnt_HVOverVoltFailureMFOP
    require port NePWDR_Cnt_HVOverVoltFailureMFOP_Rx: nv-require-com-spec{init-value=Value:0, variable=NePWDR_Cnt_HVOverVoltFailureMFOP}, required-interface=NePWDR_Cnt_HVOverVoltFailureMFOP
    provide port NeVLDR_Cnt_EEXV_TempElctrFlt_MFOP: nv-provide-com-spec{ram-block-init-value=Value:0, rom-block-init-value=Value:0, variable=NeVLDR_Cnt_EEXV_TempElctrFlt_MFOP}, provided-interface=NeVLDR_Cnt_EEXV_TempElctrFlt_MFOP
    require port NeVLDR_Cnt_EEXV_TempElctrFlt_MFOP_Rx: nv-require-com-spec{init-value=Value:0, variable=NeVLDR_Cnt_EEXV_TempElctrFlt_MFOP}, required-interface=NeVLDR_Cnt_EEXV_TempElctrFlt_MFOP
    provide port NePWDR_Cnt_BattOverTempFailureMFOP: nv-provide-com-spec{ram-block-init-value=Value:0, rom-block-init-value=Value:0, variable=NePWDR_Cnt_BattOverTempFailureMFOP}, provided-interface=NePWDR_Cnt_BattOverTempFailureMFOP
    require port NePWDR_Cnt_BattOverTempFailureMFOP_Rx: nv-require-com-spec{init-value=Value:0, variable=NePWDR_Cnt_BattOverTempFailureMFOP}, required-interface=NePWDR_Cnt_BattOverTempFailureMFOP
    provide port NeVLDR_Cnt_EEXV_PressSens_MFOP: nv-provide-com-spec{ram-block-init-value=Value:0, rom-block-init-value=Value:0, variable=NeVLDR_Cnt_EEXV_PressSens_MFOP}, provided-interface=NeVLDR_Cnt_EEXV_PressSens_MFOP
    require port NeVLDR_Cnt_EEXV_PressSens_MFOP_Rx: nv-require-com-spec{init-value=Value:0, variable=NeVLDR_Cnt_EEXV_PressSens_MFOP}, required-interface=NeVLDR_Cnt_EEXV_PressSens_MFOP
    provide port NeVLDR_Cnt_EXV_PerfDiag_MFOP: nv-provide-com-spec{ram-block-init-value=Value:0, rom-block-init-value=Value:0, variable=NeVLDR_Cnt_EXV_PerfDiag_MFOP}, provided-interface=NeVLDR_Cnt_EXV_PerfDiag_MFOP
    require port NeVLDR_Cnt_EXV_PerfDiag_MFOP_Rx: nv-require-com-spec{init-value=Value:0, variable=NeVLDR_Cnt_EXV_PerfDiag_MFOP}, required-interface=NeVLDR_Cnt_EXV_PerfDiag_MFOP
    provide port NePMDR_Cnt_BF1SysVoltHi_MFOP: nv-provide-com-spec{ram-block-init-value=Value:0, rom-block-init-value=Value:0, variable=NePMDR_Cnt_BF1SysVoltHi_MFOP}, provided-interface=NePMDR_Cnt_BF1SysVoltHi_MFOP
    require port NePMDR_Cnt_BF1SysVoltHi_MFOP_Rx: nv-require-com-spec{init-value=Value:0, variable=NePMDR_Cnt_BF1SysVoltHi_MFOP}, required-interface=NePMDR_Cnt_BF1SysVoltHi_MFOP
    provide port NePMDR_Cnt_BFHBSpareSysVoltHi_MFOP: nv-provide-com-spec{ram-block-init-value=Value:0, rom-block-init-value=Value:0, variable=NePMDR_Cnt_BFHBSpareSysVoltHi_MFOP}, provided-interface=NePMDR_Cnt_BFHBSpareSysVoltHi_MFOP
    require port NePMDR_Cnt_BFHBSpareSysVoltHi_MFOP_Rx: nv-require-com-spec{init-value=Value:0, variable=NePMDR_Cnt_BFHBSpareSysVoltHi_MFOP}, required-interface=NePMDR_Cnt_BFHBSpareSysVoltHi_MFOP
    provide port NePMDR_Cnt_BF3SysVoltLow_MFOP: nv-provide-com-spec{ram-block-init-value=Value:0, rom-block-init-value=Value:0, variable=NePMDR_Cnt_BF3SysVoltLow_MFOP}, provided-interface=NePMDR_Cnt_BF3SysVoltLow_MFOP
    require port NePMDR_Cnt_BF3SysVoltLow_MFOP_Rx: nv-require-com-spec{init-value=Value:0, variable=NePMDR_Cnt_BF3SysVoltLow_MFOP}, required-interface=NePMDR_Cnt_BF3SysVoltLow_MFOP
    provide port NeVLDR_Cnt_OEXV_PressElctrFlt_MFOP: nv-provide-com-spec{ram-block-init-value=Value:0, rom-block-init-value=Value:0, variable=NeVLDR_Cnt_OEXV_PressElctrFlt_MFOP}, provided-interface=NeVLDR_Cnt_OEXV_PressElctrFlt_MFOP
    require port NeVLDR_Cnt_OEXV_PressElctrFlt_MFOP_Rx: nv-require-com-spec{init-value=Value:0, variable=NeVLDR_Cnt_OEXV_PressElctrFlt_MFOP}, required-interface=NeVLDR_Cnt_OEXV_PressElctrFlt_MFOP
    provide port NeVLDR_Cnt_OEXV_PressSens_MFOP: nv-provide-com-spec{ram-block-init-value=Value:0, rom-block-init-value=Value:0, variable=NeVLDR_Cnt_OEXV_PressSens_MFOP}, provided-interface=NeVLDR_Cnt_OEXV_PressSens_MFOP
    require port NeVLDR_Cnt_OEXV_PressSens_MFOP_Rx: nv-require-com-spec{init-value=Value:0, variable=NeVLDR_Cnt_OEXV_PressSens_MFOP}, required-interface=NeVLDR_Cnt_OEXV_PressSens_MFOP
    provide port NePMDR_Cnt_BF3SysVoltHi_MFOP: nv-provide-com-spec{ram-block-init-value=Value:0, rom-block-init-value=Value:0, variable=NePMDR_Cnt_BF3SysVoltHi_MFOP}, provided-interface=NePMDR_Cnt_BF3SysVoltHi_MFOP
    require port NePMDR_Cnt_BF3SysVoltHi_MFOP_Rx: nv-require-com-spec{init-value=Value:0, variable=NePMDR_Cnt_BF3SysVoltHi_MFOP}, required-interface=NePMDR_Cnt_BF3SysVoltHi_MFOP
    provide port NePMDR_Cnt_BF2SysVoltLow_MFOP: nv-provide-com-spec{ram-block-init-value=Value:0, rom-block-init-value=Value:0, variable=NePMDR_Cnt_BF2SysVoltLow_MFOP}, provided-interface=NePMDR_Cnt_BF2SysVoltLow_MFOP
    require port NePMDR_Cnt_BF2SysVoltLow_MFOP_Rx: nv-require-com-spec{init-value=Value:0, variable=NePMDR_Cnt_BF2SysVoltLow_MFOP}, required-interface=NePMDR_Cnt_BF2SysVoltLow_MFOP
    provide port NePMDR_Cnt_BF2SysVoltHi_MFOP: nv-provide-com-spec{ram-block-init-value=Value:0, rom-block-init-value=Value:0, variable=NePMDR_Cnt_BF2SysVoltHi_MFOP}, provided-interface=NePMDR_Cnt_BF2SysVoltHi_MFOP
    require port NePMDR_Cnt_BF2SysVoltHi_MFOP_Rx: nv-require-com-spec{init-value=Value:0, variable=NePMDR_Cnt_BF2SysVoltHi_MFOP}, required-interface=NePMDR_Cnt_BF2SysVoltHi_MFOP
    provide port NePMDR_Cnt_BF1SysVoltLow_MFOP: nv-provide-com-spec{ram-block-init-value=Value:0, rom-block-init-value=Value:0, variable=NePMDR_Cnt_BF1SysVoltLow_MFOP}, provided-interface=NePMDR_Cnt_BF1SysVoltLow_MFOP
    require port NePMDR_Cnt_BF1SysVoltLow_MFOP_Rx: nv-require-com-spec{init-value=Value:0, variable=NePMDR_Cnt_BF1SysVoltLow_MFOP}, required-interface=NePMDR_Cnt_BF1SysVoltLow_MFOP
    provide port NePMDD_Cnt_RunLoMaxFOP: nv-provide-com-spec{ram-block-init-value=Value:0, rom-block-init-value=Value:0, variable=NePMDD_Cnt_RunLoMaxFOP}, provided-interface=NePMDD_Cnt_RunLoMaxFOP
    require port NePMDD_Cnt_RunLoMaxFOP_Rx: nv-require-com-spec{init-value=Value:0, variable=NePMDD_Cnt_RunLoMaxFOP}, required-interface=NePMDD_Cnt_RunLoMaxFOP
    provide port NeVLDR_Cnt_EXV_PressElctrFlt_MFOP: nv-provide-com-spec{ram-block-init-value=Value:0, rom-block-init-value=Value:0, variable=NeVLDR_Cnt_EXV_PressElctrFlt_MFOP}, provided-interface=NeVLDR_Cnt_EXV_PressElctrFlt_MFOP
    require port NeVLDR_Cnt_EXV_PressElctrFlt_MFOP_Rx: nv-require-com-spec{init-value=Value:0, variable=NeVLDR_Cnt_EXV_PressElctrFlt_MFOP}, required-interface=NeVLDR_Cnt_EXV_PressElctrFlt_MFOP
    provide port NeVLDR_Cnt_OEXV_TempElctrFlt_MFOP: nv-provide-com-spec{ram-block-init-value=Value:0, rom-block-init-value=Value:0, variable=NeVLDR_Cnt_OEXV_TempElctrFlt_MFOP}, provided-interface=NeVLDR_Cnt_OEXV_TempElctrFlt_MFOP
    require port NeVLDR_Cnt_OEXV_TempElctrFlt_MFOP_Rx: nv-require-com-spec{init-value=Value:0, variable=NeVLDR_Cnt_OEXV_TempElctrFlt_MFOP}, required-interface=NeVLDR_Cnt_OEXV_TempElctrFlt_MFOP
    provide port NeAADR_Cnt_AAD_PerfDiag_MFOP: nv-provide-com-spec{ram-block-init-value=Value:0, rom-block-init-value=Value:0, variable=NeAADR_Cnt_AAD_PerfDiag_MFOP}, provided-interface=NeAADR_Cnt_AAD_PerfDiag_MFOP
    require port NeAADR_Cnt_AAD_PerfDiag_MFOP_Rx: nv-require-com-spec{init-value=Value:0, variable=NeAADR_Cnt_AAD_PerfDiag_MFOP}, required-interface=NeAADR_Cnt_AAD_PerfDiag_MFOP
    provide port NePMDD_Cnt_RunCrankOpenMaxFOP: nv-provide-com-spec{ram-block-init-value=Value:0, rom-block-init-value=Value:0, variable=NePMDD_Cnt_RunCrankOpenMaxFOP}, provided-interface=NePMDD_Cnt_RunCrankOpenMaxFOP
    require port NePMDD_Cnt_RunCrankOpenMaxFOP_Rx: nv-require-com-spec{init-value=Value:0, variable=NePMDD_Cnt_RunCrankOpenMaxFOP}, required-interface=NePMDD_Cnt_RunCrankOpenMaxFOP
    provide port NePMDD_Cnt_RunCrankHiMaxFOP: nv-provide-com-spec{ram-block-init-value=Value:0, rom-block-init-value=Value:0, variable=NePMDD_Cnt_RunCrankHiMaxFOP}, provided-interface=NePMDD_Cnt_RunCrankHiMaxFOP
    require port NePMDD_Cnt_RunCrankHiMaxFOP_Rx: nv-require-com-spec{init-value=Value:0, variable=NePMDD_Cnt_RunCrankHiMaxFOP}, required-interface=NePMDD_Cnt_RunCrankHiMaxFOP
    provide port NePMDD_Cnt_AccLoMaxFOP: nv-provide-com-spec{ram-block-init-value=Value:0, rom-block-init-value=Value:0, variable=NePMDD_Cnt_AccLoMaxFOP}, provided-interface=NePMDD_Cnt_AccLoMaxFOP
    require port NePMDD_Cnt_AccLoMaxFOP_Rx: nv-require-com-spec{init-value=Value:0, variable=NePMDD_Cnt_AccLoMaxFOP}, required-interface=NePMDD_Cnt_AccLoMaxFOP
    provide port NePMDD_Cnt_AccHiMaxFOP: nv-provide-com-spec{ram-block-init-value=Value:0, rom-block-init-value=Value:0, variable=NePMDD_Cnt_AccHiMaxFOP}, provided-interface=NePMDD_Cnt_AccHiMaxFOP
    require port NePMDD_Cnt_AccHiMaxFOP_Rx: nv-require-com-spec{init-value=Value:0, variable=NePMDD_Cnt_AccHiMaxFOP}, required-interface=NePMDD_Cnt_AccHiMaxFOP
    provide port NePMDR_Cnt_BFHBSysVoltHi_MFOP: nv-provide-com-spec{ram-block-init-value=Value:0, rom-block-init-value=Value:0, variable=NePMDR_Cnt_BFHBSysVoltHi_MFOP}, provided-interface=NePMDR_Cnt_BFHBSysVoltHi_MFOP
    require port NePMDR_Cnt_BFHBSysVoltHi_MFOP_Rx: nv-require-com-spec{init-value=Value:0, variable=NePMDR_Cnt_BFHBSysVoltHi_MFOP}, required-interface=NePMDR_Cnt_BFHBSysVoltHi_MFOP
    provide port NePMDR_Cnt_HBSpareSysVoltLow_MFOP: nv-provide-com-spec{ram-block-init-value=Value:0, rom-block-init-value=Value:0, variable=NePMDR_Cnt_HBSpareSysVoltLow_MFOP}, provided-interface=NePMDR_Cnt_HBSpareSysVoltLow_MFOP
    require port NePMDR_Cnt_HBSpareSysVoltLow_MFOP_Rx: nv-require-com-spec{init-value=Value:0, variable=NePMDR_Cnt_HBSpareSysVoltLow_MFOP}, required-interface=NePMDR_Cnt_HBSpareSysVoltLow_MFOP
    provide port NePMDR_Cnt_HBSysVoltLow_MFOP: nv-provide-com-spec{ram-block-init-value=Value:0, rom-block-init-value=Value:0, variable=NePMDR_Cnt_HBSysVoltLow_MFOP}, provided-interface=NePMDR_Cnt_HBSysVoltLow_MFOP
    require port NePMDR_Cnt_HBSysVoltLow_MFOP_Rx: nv-require-com-spec{init-value=Value:0, variable=NePMDR_Cnt_HBSysVoltLow_MFOP}, required-interface=NePMDR_Cnt_HBSysVoltLow_MFOP
    provide port NePWDR_Cnt_HVUnderVoltFailureMFOP: nv-provide-com-spec{ram-block-init-value=Value:0, rom-block-init-value=Value:0, variable=NePWDR_Cnt_HVUnderVoltFailureMFOP}, provided-interface=NePWDR_Cnt_HVUnderVoltFailureMFOP
    require port NePWDR_Cnt_HVUnderVoltFailureMFOP_Rx: nv-require-com-spec{init-value=Value:0, variable=NePWDR_Cnt_HVUnderVoltFailureMFOP}, required-interface=NePWDR_Cnt_HVUnderVoltFailureMFOP
    provide port NeVLDR_Cnt_EXV_PressSens_MFOP: nv-provide-com-spec{ram-block-init-value=Value:0, rom-block-init-value=Value:0, variable=NeVLDR_Cnt_EXV_PressSens_MFOP}, provided-interface=NeVLDR_Cnt_EXV_PressSens_MFOP
    require port NeVLDR_Cnt_EXV_PressSens_MFOP_Rx: nv-require-com-spec{init-value=Value:0, variable=NeVLDR_Cnt_EXV_PressSens_MFOP}, required-interface=NeVLDR_Cnt_EXV_PressSens_MFOP
    provide port NeVLDR_Cnt_EXV_TempElctrFlt_MFOP: nv-provide-com-spec{ram-block-init-value=Value:0, rom-block-init-value=Value:0, variable=NeVLDR_Cnt_EXV_TempElctrFlt_MFOP}, provided-interface=NeVLDR_Cnt_EXV_TempElctrFlt_MFOP
    require port NeVLDR_Cnt_EXV_TempElctrFlt_MFOP_Rx: nv-require-com-spec{init-value=Value:0, variable=NeVLDR_Cnt_EXV_TempElctrFlt_MFOP}, required-interface=NeVLDR_Cnt_EXV_TempElctrFlt_MFOP
    provide port NeVLDR_Cnt_EXV_TempSens_MFOP: nv-provide-com-spec{ram-block-init-value=Value:0, rom-block-init-value=Value:0, variable=NeVLDR_Cnt_EXV_TempSens_MFOP}, provided-interface=NeVLDR_Cnt_EXV_TempSens_MFOP
    require port NeVLDR_Cnt_EXV_TempSens_MFOP_Rx: nv-require-com-spec{init-value=Value:0, variable=NeVLDR_Cnt_EXV_TempSens_MFOP}, required-interface=NeVLDR_Cnt_EXV_TempSens_MFOP
    provide port NeVLDR_Cnt_HCTV_Leak_MFOP: nv-provide-com-spec{ram-block-init-value=Value:0, rom-block-init-value=Value:0, variable=NeVLDR_Cnt_HCTV_Leak_MFOP}, provided-interface=NeVLDR_Cnt_HCTV_Leak_MFOP
    require port NeVLDR_Cnt_HCTV_Leak_MFOP_Rx: nv-require-com-spec{init-value=Value:0, variable=NeVLDR_Cnt_HCTV_Leak_MFOP}, required-interface=NeVLDR_Cnt_HCTV_Leak_MFOP
    provide port NeVLDR_Cnt_HTL_PerfDiag_MFOP: nv-provide-com-spec{ram-block-init-value=Value:0, rom-block-init-value=Value:0, variable=NeVLDR_Cnt_HTL_PerfDiag_MFOP}, provided-interface=NeVLDR_Cnt_HTL_PerfDiag_MFOP
    require port NeVLDR_Cnt_HTL_PerfDiag_MFOP_Rx: nv-require-com-spec{init-value=Value:0, variable=NeVLDR_Cnt_HTL_PerfDiag_MFOP}, required-interface=NeVLDR_Cnt_HTL_PerfDiag_MFOP
    provide port NeVLDR_Cnt_HTSoV_StkCls_MFOP: nv-provide-com-spec{ram-block-init-value=Value:0, rom-block-init-value=Value:0, variable=NeVLDR_Cnt_HTSoV_StkCls_MFOP}, provided-interface=NeVLDR_Cnt_HTSoV_StkCls_MFOP
    require port NeVLDR_Cnt_HTSoV_StkCls_MFOP_Rx: nv-require-com-spec{init-value=Value:0, variable=NeVLDR_Cnt_HTSoV_StkCls_MFOP}, required-interface=NeVLDR_Cnt_HTSoV_StkCls_MFOP
    provide port NePWDR_Cnt_BPCM_MFOP: nv-provide-com-spec{ram-block-init-value=Value:0, rom-block-init-value=Value:0, variable=NePWDR_Cnt_BPCM_MFOP}, provided-interface=NePWDR_Cnt_BPCM_MFOP
    require port NePWDR_Cnt_BPCM_MFOP_Rx: nv-require-com-spec{init-value=Value:0, variable=NePWDR_Cnt_BPCM_MFOP}, required-interface=NePWDR_Cnt_BPCM_MFOP
    provide port NeVLDR_Cnt_HTSoV_StkOpn_MFOP: nv-provide-com-spec{ram-block-init-value=Value:0, rom-block-init-value=Value:0, variable=NeVLDR_Cnt_HTSoV_StkOpn_MFOP}, provided-interface=NeVLDR_Cnt_HTSoV_StkOpn_MFOP
    require port NeVLDR_Cnt_HTSoV_StkOpn_MFOP_Rx: nv-require-com-spec{init-value=Value:0, variable=NeVLDR_Cnt_HTSoV_StkOpn_MFOP}, required-interface=NeVLDR_Cnt_HTSoV_StkOpn_MFOP
    provide port NeVLDR_Cnt_LTR_PerfDiag_MFOP: nv-provide-com-spec{ram-block-init-value=Value:0, rom-block-init-value=Value:0, variable=NeVLDR_Cnt_LTR_PerfDiag_MFOP}, provided-interface=NeVLDR_Cnt_LTR_PerfDiag_MFOP
    require port NeVLDR_Cnt_LTR_PerfDiag_MFOP_Rx: nv-require-com-spec{init-value=Value:0, variable=NeVLDR_Cnt_LTR_PerfDiag_MFOP}, required-interface=NeVLDR_Cnt_LTR_PerfDiag_MFOP
    provide port NeVLDR_Cnt_LTSOV_StkOff_MFOP: nv-provide-com-spec{ram-block-init-value=Value:0, rom-block-init-value=Value:0, variable=NeVLDR_Cnt_LTSOV_StkOff_MFOP}, provided-interface=NeVLDR_Cnt_LTSOV_StkOff_MFOP
    require port NeVLDR_Cnt_LTSOV_StkOff_MFOP_Rx: nv-require-com-spec{init-value=Value:0, variable=NeVLDR_Cnt_LTSOV_StkOff_MFOP}, required-interface=NeVLDR_Cnt_LTSOV_StkOff_MFOP
    provide port NeVLDR_Cnt_LTSOV_StkOn_MFOP: nv-provide-com-spec{ram-block-init-value=Value:0, rom-block-init-value=Value:0, variable=NeVLDR_Cnt_LTSOV_StkOn_MFOP}, provided-interface=NeVLDR_Cnt_LTSOV_StkOn_MFOP
    require port NeVLDR_Cnt_LTSOV_StkOn_MFOP_Rx: nv-require-com-spec{init-value=Value:0, variable=NeVLDR_Cnt_LTSOV_StkOn_MFOP}, required-interface=NeVLDR_Cnt_LTSOV_StkOn_MFOP
    provide port NeVLDR_Cnt_OEXV_PerfDiag_MFOP: nv-provide-com-spec{ram-block-init-value=Value:0, rom-block-init-value=Value:0, variable=NeVLDR_Cnt_OEXV_PerfDiag_MFOP}, provided-interface=NeVLDR_Cnt_OEXV_PerfDiag_MFOP
    require port NeVLDR_Cnt_OEXV_PerfDiag_MFOP_Rx: nv-require-com-spec{init-value=Value:0, variable=NeVLDR_Cnt_OEXV_PerfDiag_MFOP}, required-interface=NeVLDR_Cnt_OEXV_PerfDiag_MFOP
    provide port NePWDR_Cnt_HVOverVoltWarnMSOF: nv-provide-com-spec{ram-block-init-value=Value:65535, rom-block-init-value=Value:65535, variable=NePWDR_Cnt_HVOverVoltWarnMSOF}, provided-interface=NePWDR_Cnt_HVOverVoltWarnMSOF
    require port NePWDR_Cnt_HVOverVoltWarnMSOF_Rx: nv-require-com-spec{init-value=Value:65535, variable=NePWDR_Cnt_HVOverVoltWarnMSOF}, required-interface=NePWDR_Cnt_HVOverVoltWarnMSOF
    provide port NeTHDR_Cnt_OEXV_In_MFOP: nv-provide-com-spec{ram-block-init-value=Value:0, rom-block-init-value=Value:0, variable=NeTHDR_Cnt_OEXV_In_MFOP}, provided-interface=NeTHDR_Cnt_OEXV_In_MFOP
    require port NeTHDR_Cnt_OEXV_In_MFOP_Rx: nv-require-com-spec{init-value=Value:0, variable=NeTHDR_Cnt_OEXV_In_MFOP}, required-interface=NeTHDR_Cnt_OEXV_In_MFOP
    provide port NePWDR_Cnt_HVUnderVoltFailureMSOF: nv-provide-com-spec{ram-block-init-value=Value:65535, rom-block-init-value=Value:65535, variable=NePWDR_Cnt_HVUnderVoltFailureMSOF}, provided-interface=NePWDR_Cnt_HVUnderVoltFailureMSOF
    require port NePWDR_Cnt_HVUnderVoltFailureMSOF_Rx: nv-require-com-spec{init-value=Value:65535, variable=NePWDR_Cnt_HVUnderVoltFailureMSOF}, required-interface=NePWDR_Cnt_HVUnderVoltFailureMSOF
    provide port NeTHDR_Cnt_InTmpSns_MFOP: nv-provide-com-spec{ram-block-init-value=Value:0, rom-block-init-value=Value:0, variable=NeTHDR_Cnt_InTmpSns_MFOP}, provided-interface=NeTHDR_Cnt_InTmpSns_MFOP
    require port NeTHDR_Cnt_InTmpSns_MFOP_Rx: nv-require-com-spec{init-value=Value:0, variable=NeTHDR_Cnt_InTmpSns_MFOP}, required-interface=NeTHDR_Cnt_InTmpSns_MFOP
    provide port NeTHDR_Cnt_HTAP_MFOP: nv-provide-com-spec{ram-block-init-value=Value:0, rom-block-init-value=Value:0, variable=NeTHDR_Cnt_HTAP_MFOP}, provided-interface=NeTHDR_Cnt_HTAP_MFOP
    require port NeTHDR_Cnt_HTAP_MFOP_Rx: nv-require-com-spec{init-value=Value:0, variable=NeTHDR_Cnt_HTAP_MFOP}, required-interface=NeTHDR_Cnt_HTAP_MFOP
    provide port NeTHDR_Cnt_HCCTOS_MFOP: nv-provide-com-spec{ram-block-init-value=Value:0, rom-block-init-value=Value:0, variable=NeTHDR_Cnt_HCCTOS_MFOP}, provided-interface=NeTHDR_Cnt_HCCTOS_MFOP
    require port NeTHDR_Cnt_HCCTOS_MFOP_Rx: nv-require-com-spec{init-value=Value:0, variable=NeTHDR_Cnt_HCCTOS_MFOP}, required-interface=NeTHDR_Cnt_HCCTOS_MFOP
    provide port NeSCPR_e_NxtSchCH_StrtDay: nv-provide-com-spec{ram-block-init-value=Value:0, rom-block-init-value=Value:0, variable=NeSCPR_e_NxtSchCH_StrtDay}, provided-interface=NeSCPR_e_NxtSchCH_StrtDay
    require port NeSCPR_e_NxtSchCH_StrtDay_Rx: nv-require-com-spec{init-value=Value:0, variable=NeSCPR_e_NxtSchCH_StrtDay}, required-interface=NeSCPR_e_NxtSchCH_StrtDay
    provide port NeSCPR_e_NxtSchCH_EndMin: nv-provide-com-spec{ram-block-init-value=Value:0, rom-block-init-value=Value:0, variable=NeSCPR_e_NxtSchCH_EndMin}, provided-interface=NeSCPR_e_NxtSchCH_EndMin
    require port NeSCPR_e_NxtSchCH_EndMin_Rx: nv-require-com-spec{init-value=Value:0, variable=NeSCPR_e_NxtSchCH_EndMin}, required-interface=NeSCPR_e_NxtSchCH_EndMin
    provide port NeSCPR_e_NxtSchCH_StrtMin: nv-provide-com-spec{ram-block-init-value=Value:0, rom-block-init-value=Value:0, variable=NeSCPR_e_NxtSchCH_StrtMin}, provided-interface=NeSCPR_e_NxtSchCH_StrtMin
    require port NeSCPR_e_NxtSchCH_StrtMin_Rx: nv-require-com-spec{init-value=Value:0, variable=NeSCPR_e_NxtSchCH_StrtMin}, required-interface=NeSCPR_e_NxtSchCH_StrtMin
    provide port NeSCPR_e_NxtSchCH_EndHr: nv-provide-com-spec{ram-block-init-value=Value:0, rom-block-init-value=Value:0, variable=NeSCPR_e_NxtSchCH_EndHr}, provided-interface=NeSCPR_e_NxtSchCH_EndHr
    require port NeSCPR_e_NxtSchCH_EndHr_Rx: nv-require-com-spec{init-value=Value:0, variable=NeSCPR_e_NxtSchCH_EndHr}, required-interface=NeSCPR_e_NxtSchCH_EndHr
    provide port NeSCPR_e_NxtSchCH_EndDay: nv-provide-com-spec{ram-block-init-value=Value:0, rom-block-init-value=Value:0, variable=NeSCPR_e_NxtSchCH_EndDay}, provided-interface=NeSCPR_e_NxtSchCH_EndDay
    require port NeSCPR_e_NxtSchCH_EndDay_Rx: nv-require-com-spec{init-value=Value:0, variable=NeSCPR_e_NxtSchCH_EndDay}, required-interface=NeSCPR_e_NxtSchCH_EndDay
    provide port NeSCPR_e_LastNowIndex: nv-provide-com-spec{ram-block-init-value=Value:0, rom-block-init-value=Value:0, variable=NeSCPR_e_LastNowIndex}, provided-interface=NeSCPR_e_LastNowIndex
    require port NeSCPR_e_LastNowIndex_Rx: nv-require-com-spec{init-value=Value:0, variable=NeSCPR_e_LastNowIndex}, required-interface=NeSCPR_e_LastNowIndex
    provide port NeSCPR_e_EndIndexCanc: nv-provide-com-spec{ram-block-init-value=Value:0, rom-block-init-value=Value:0, variable=NeSCPR_e_EndIndexCanc}, provided-interface=NeSCPR_e_EndIndexCanc
    require port NeSCPR_e_EndIndexCanc_Rx: nv-require-com-spec{init-value=Value:0, variable=NeSCPR_e_EndIndexCanc}, required-interface=NeSCPR_e_EndIndexCanc
    provide port NeSCPR_e_CancelStartIndx: nv-provide-com-spec{ram-block-init-value=Value:0, rom-block-init-value=Value:0, variable=NeSCPR_e_CancelStartIndx}, provided-interface=NeSCPR_e_CancelStartIndx
    require port NeSCPR_e_CancelStartIndx_Rx: nv-require-com-spec{init-value=Value:0, variable=NeSCPR_e_CancelStartIndx}, required-interface=NeSCPR_e_CancelStartIndx
    provide port NeSCPR_e_CancStartIdxHold: nv-provide-com-spec{ram-block-init-value=Value:0, rom-block-init-value=Value:0, variable=NeSCPR_e_CancStartIdxHold}, provided-interface=NeSCPR_e_CancStartIdxHold
    require port NeSCPR_e_CancStartIdxHold_Rx: nv-require-com-spec{init-value=Value:0, variable=NeSCPR_e_CancStartIdxHold}, required-interface=NeSCPR_e_CancStartIdxHold
    provide port NeSCPR_e_NxtSchCH_StrtHr: nv-provide-com-spec{ram-block-init-value=Value:0, rom-block-init-value=Value:0, variable=NeSCPR_e_NxtSchCH_StrtHr}, provided-interface=NeSCPR_e_NxtSchCH_StrtHr
    require port NeSCPR_e_NxtSchCH_StrtHr_Rx: nv-require-com-spec{init-value=Value:0, variable=NeSCPR_e_NxtSchCH_StrtHr}, required-interface=NeSCPR_e_NxtSchCH_StrtHr
    provide port NeSCPR_e_Sch2CoCH_StopMin: nv-provide-com-spec{ram-block-init-value=Value:0, rom-block-init-value=Value:0, variable=NeSCPR_e_Sch2CoCH_StopMin}, provided-interface=NeSCPR_e_Sch2CoCH_StopMin
    require port NeSCPR_e_Sch2CoCH_StopMin_Rx: nv-require-com-spec{init-value=Value:0, variable=NeSCPR_e_Sch2CoCH_StopMin}, required-interface=NeSCPR_e_Sch2CoCH_StopMin
    provide port NeTHDR_Cnt_OEXV_Out_MFOP: nv-provide-com-spec{ram-block-init-value=Value:0, rom-block-init-value=Value:0, variable=NeTHDR_Cnt_OEXV_Out_MFOP}, provided-interface=NeTHDR_Cnt_OEXV_Out_MFOP
    require port NeTHDR_Cnt_OEXV_Out_MFOP_Rx: nv-require-com-spec{init-value=Value:0, variable=NeTHDR_Cnt_OEXV_Out_MFOP}, required-interface=NeTHDR_Cnt_OEXV_Out_MFOP
    provide port NeTHDR_Cnt_OOCTOS_MFOP: nv-provide-com-spec{ram-block-init-value=Value:0, rom-block-init-value=Value:0, variable=NeTHDR_Cnt_OOCTOS_MFOP}, provided-interface=NeTHDR_Cnt_OOCTOS_MFOP
    require port NeTHDR_Cnt_OOCTOS_MFOP_Rx: nv-require-com-spec{init-value=Value:0, variable=NeTHDR_Cnt_OOCTOS_MFOP}, required-interface=NeTHDR_Cnt_OOCTOS_MFOP
    provide port NeTHDR_Cnt_PPCTIS_MFOP: nv-provide-com-spec{ram-block-init-value=Value:0, rom-block-init-value=Value:0, variable=NeTHDR_Cnt_PPCTIS_MFOP}, provided-interface=NeTHDR_Cnt_PPCTIS_MFOP
    require port NeTHDR_Cnt_PPCTIS_MFOP_Rx: nv-require-com-spec{init-value=Value:0, variable=NeTHDR_Cnt_PPCTIS_MFOP}, required-interface=NeTHDR_Cnt_PPCTIS_MFOP
    provide port NeTHDR_Cnt_PPCTIS_OT_MSOP: nv-provide-com-spec{ram-block-init-value=Value:0, rom-block-init-value=Value:0, variable=NeTHDR_Cnt_PPCTIS_OT_MSOP}, provided-interface=NeTHDR_Cnt_PPCTIS_OT_MSOP
    require port NeTHDR_Cnt_PPCTIS_OT_MSOP_Rx: nv-require-com-spec{init-value=Value:0, variable=NeTHDR_Cnt_PPCTIS_OT_MSOP}, required-interface=NeTHDR_Cnt_PPCTIS_OT_MSOP
    provide port NeTHDR_Cnt_LTPP2_MFOP: nv-provide-com-spec{ram-block-init-value=Value:0, rom-block-init-value=Value:0, variable=NeTHDR_Cnt_LTPP2_MFOP}, provided-interface=NeTHDR_Cnt_LTPP2_MFOP
    require port NeTHDR_Cnt_LTPP2_MFOP_Rx: nv-require-com-spec{init-value=Value:0, variable=NeTHDR_Cnt_LTPP2_MFOP}, required-interface=NeTHDR_Cnt_LTPP2_MFOP
    provide port NeTHDR_Cnt_LRCTOS_MFOP: nv-provide-com-spec{ram-block-init-value=Value:0, rom-block-init-value=Value:0, variable=NeTHDR_Cnt_LRCTOS_MFOP}, provided-interface=NeTHDR_Cnt_LRCTOS_MFOP
    require port NeTHDR_Cnt_LRCTOS_MFOP_Rx: nv-require-com-spec{init-value=Value:0, variable=NeTHDR_Cnt_LRCTOS_MFOP}, required-interface=NeTHDR_Cnt_LRCTOS_MFOP
    provide port NeTIDR_Cnt_EngTrqHiFlt_MFOP: nv-provide-com-spec{ram-block-init-value=Value:0, rom-block-init-value=Value:0, variable=NeTIDR_Cnt_EngTrqHiFlt_MFOP}, provided-interface=NeTIDR_Cnt_EngTrqHiFlt_MFOP
    require port NeTIDR_Cnt_EngTrqHiFlt_MFOP_Rx: nv-require-com-spec{init-value=Value:0, variable=NeTIDR_Cnt_EngTrqHiFlt_MFOP}, required-interface=NeTIDR_Cnt_EngTrqHiFlt_MFOP
    provide port NeTIDR_Cnt_EngTrqHiFlt_MSOF: nv-provide-com-spec{ram-block-init-value=Value:0, rom-block-init-value=Value:0, variable=NeTIDR_Cnt_EngTrqHiFlt_MSOF}, provided-interface=NeTIDR_Cnt_EngTrqHiFlt_MSOF
    require port NeTIDR_Cnt_EngTrqHiFlt_MSOF_Rx: nv-require-com-spec{init-value=Value:0, variable=NeTIDR_Cnt_EngTrqHiFlt_MSOF}, required-interface=NeTIDR_Cnt_EngTrqHiFlt_MSOF
    provide port NeSCPR_e_Sch2CoCH_StopHr: nv-provide-com-spec{ram-block-init-value=Value:0, rom-block-init-value=Value:0, variable=NeSCPR_e_Sch2CoCH_StopHr}, provided-interface=NeSCPR_e_Sch2CoCH_StopHr
    require port NeSCPR_e_Sch2CoCH_StopHr_Rx: nv-require-com-spec{init-value=Value:0, variable=NeSCPR_e_Sch2CoCH_StopHr}, required-interface=NeSCPR_e_Sch2CoCH_StopHr
    provide port NeTISD_Cnt_SpdRatlFlt_MFOP: nv-provide-com-spec{ram-block-init-value=Value:0, rom-block-init-value=Value:0, variable=NeTISD_Cnt_SpdRatlFlt_MFOP}, provided-interface=NeTISD_Cnt_SpdRatlFlt_MFOP
    require port NeTISD_Cnt_SpdRatlFlt_MFOP_Rx: nv-require-com-spec{init-value=Value:0, variable=NeTISD_Cnt_SpdRatlFlt_MFOP}, required-interface=NeTISD_Cnt_SpdRatlFlt_MFOP
    provide port NeSCPR_e_Sch1CoCH_StopMin: nv-provide-com-spec{ram-block-init-value=Value:0, rom-block-init-value=Value:0, variable=NeSCPR_e_Sch1CoCH_StopMin}, provided-interface=NeSCPR_e_Sch1CoCH_StopMin
    require port NeSCPR_e_Sch1CoCH_StopMin_Rx: nv-require-com-spec{init-value=Value:0, variable=NeSCPR_e_Sch1CoCH_StopMin}, required-interface=NeSCPR_e_Sch1CoCH_StopMin
    provide port NeSCPR_e_Sch1CoCH_StopHr: nv-provide-com-spec{ram-block-init-value=Value:0, rom-block-init-value=Value:0, variable=NeSCPR_e_Sch1CoCH_StopHr}, provided-interface=NeSCPR_e_Sch1CoCH_StopHr
    require port NeSCPR_e_Sch1CoCH_StopHr_Rx: nv-require-com-spec{init-value=Value:0, variable=NeSCPR_e_Sch1CoCH_StopHr}, required-interface=NeSCPR_e_Sch1CoCH_StopHr
    provide port NeTIDR_Cnt_EngTrqLoFlt_MFOP: nv-provide-com-spec{ram-block-init-value=Value:0, rom-block-init-value=Value:0, variable=NeTIDR_Cnt_EngTrqLoFlt_MFOP}, provided-interface=NeTIDR_Cnt_EngTrqLoFlt_MFOP
    require port NeTIDR_Cnt_EngTrqLoFlt_MFOP_Rx: nv-require-com-spec{init-value=Value:0, variable=NeTIDR_Cnt_EngTrqLoFlt_MFOP}, required-interface=NeTIDR_Cnt_EngTrqLoFlt_MFOP
    provide port NeTIDR_Cnt_EngTrqLoFlt_MSOF: nv-provide-com-spec{ram-block-init-value=Value:0, rom-block-init-value=Value:0, variable=NeTIDR_Cnt_EngTrqLoFlt_MSOF}, provided-interface=NeTIDR_Cnt_EngTrqLoFlt_MSOF
    require port NeTIDR_Cnt_EngTrqLoFlt_MSOF_Rx: nv-require-com-spec{init-value=Value:0, variable=NeTIDR_Cnt_EngTrqLoFlt_MSOF}, required-interface=NeTIDR_Cnt_EngTrqLoFlt_MSOF
    provide port NeTIMR_e_TrrnMdSt: nv-provide-com-spec{ram-block-init-value=Value:0, rom-block-init-value=Value:0, variable=NeTIMR_e_TrrnMdSt}, provided-interface=NeTIMR_e_TrrnMdSt
    require port NeTIMR_e_TrrnMdSt_Rx: nv-require-com-spec{init-value=Value:0, variable=NeTIMR_e_TrrnMdSt}, required-interface=NeTIMR_e_TrrnMdSt
    provide port NeSCPR_e_NxtSchCP_StrtMin: nv-provide-com-spec{ram-block-init-value=Value:0, rom-block-init-value=Value:0, variable=NeSCPR_e_NxtSchCP_StrtMin}, provided-interface=NeSCPR_e_NxtSchCP_StrtMin
    require port NeSCPR_e_NxtSchCP_StrtMin_Rx: nv-require-com-spec{init-value=Value:0, variable=NeSCPR_e_NxtSchCP_StrtMin}, required-interface=NeSCPR_e_NxtSchCP_StrtMin
    provide port NeSCPR_e_NxtSchCP_StrtHr: nv-provide-com-spec{ram-block-init-value=Value:0, rom-block-init-value=Value:0, variable=NeSCPR_e_NxtSchCP_StrtHr}, provided-interface=NeSCPR_e_NxtSchCP_StrtHr
    require port NeSCPR_e_NxtSchCP_StrtHr_Rx: nv-require-com-spec{init-value=Value:0, variable=NeSCPR_e_NxtSchCP_StrtHr}, required-interface=NeSCPR_e_NxtSchCP_StrtHr
    provide port NeSCPR_e_NxtSchCP_Day: nv-provide-com-spec{ram-block-init-value=Value:0, rom-block-init-value=Value:0, variable=NeSCPR_e_NxtSchCP_Day}, provided-interface=NeSCPR_e_NxtSchCP_Day
    require port NeSCPR_e_NxtSchCP_Day_Rx: nv-require-com-spec{init-value=Value:0, variable=NeSCPR_e_NxtSchCP_Day}, required-interface=NeSCPR_e_NxtSchCP_Day
    provide port NeTHDR_Cnt_HCCTIS_MFOP: nv-provide-com-spec{ram-block-init-value=Value:0, rom-block-init-value=Value:0, variable=NeTHDR_Cnt_HCCTIS_MFOP}, provided-interface=NeTHDR_Cnt_HCCTIS_MFOP
    require port NeTHDR_Cnt_HCCTIS_MFOP_Rx: nv-require-com-spec{init-value=Value:0, variable=NeTHDR_Cnt_HCCTIS_MFOP}, required-interface=NeTHDR_Cnt_HCCTIS_MFOP
    provide port NeTHDR_Cnt_LTPP_MFOP: nv-provide-com-spec{ram-block-init-value=Value:0, rom-block-init-value=Value:0, variable=NeTHDR_Cnt_LTPP_MFOP}, provided-interface=NeTHDR_Cnt_LTPP_MFOP
    require port NeTHDR_Cnt_LTPP_MFOP_Rx: nv-require-com-spec{init-value=Value:0, variable=NeTHDR_Cnt_LTPP_MFOP}, required-interface=NeTHDR_Cnt_LTPP_MFOP
    provide port NeTHDR_Cnt_AGS2_Perf_MFOP: nv-provide-com-spec{ram-block-init-value=Value:0, rom-block-init-value=Value:0, variable=NeTHDR_Cnt_AGS2_Perf_MFOP}, provided-interface=NeTHDR_Cnt_AGS2_Perf_MFOP
    require port NeTHDR_Cnt_AGS2_Perf_MFOP_Rx: nv-require-com-spec{init-value=Value:0, variable=NeTHDR_Cnt_AGS2_Perf_MFOP}, required-interface=NeTHDR_Cnt_AGS2_Perf_MFOP
    provide port NePWDR_Cnt_StuckHiFOP: nv-provide-com-spec{ram-block-init-value=Value:0, rom-block-init-value=Value:0, variable=NePWDR_Cnt_StuckHiFOP}, provided-interface=NePWDR_Cnt_StuckHiFOP
    require port NePWDR_Cnt_StuckHiFOP_Rx: nv-require-com-spec{init-value=Value:0, variable=NePWDR_Cnt_StuckHiFOP}, required-interface=NePWDR_Cnt_StuckHiFOP
    provide port NePWDR_Cnt_SOCLowWarnMFOP: nv-provide-com-spec{ram-block-init-value=Value:0, rom-block-init-value=Value:0, variable=NePWDR_Cnt_SOCLowWarnMFOP}, provided-interface=NePWDR_Cnt_SOCLowWarnMFOP
    require port NePWDR_Cnt_SOCLowWarnMFOP_Rx: nv-require-com-spec{init-value=Value:0, variable=NePWDR_Cnt_SOCLowWarnMFOP}, required-interface=NePWDR_Cnt_SOCLowWarnMFOP
    provide port NePWDR_Cnt_SOCLowFailureMFOP: nv-provide-com-spec{ram-block-init-value=Value:0, rom-block-init-value=Value:0, variable=NePWDR_Cnt_SOCLowFailureMFOP}, provided-interface=NePWDR_Cnt_SOCLowFailureMFOP
    require port NePWDR_Cnt_SOCLowFailureMFOP_Rx: nv-require-com-spec{init-value=Value:0, variable=NePWDR_Cnt_SOCLowFailureMFOP}, required-interface=NePWDR_Cnt_SOCLowFailureMFOP
    provide port NePWDR_Cnt_SOCHighWarnMFOP: nv-provide-com-spec{ram-block-init-value=Value:0, rom-block-init-value=Value:0, variable=NePWDR_Cnt_SOCHighWarnMFOP}, provided-interface=NePWDR_Cnt_SOCHighWarnMFOP
    require port NePWDR_Cnt_SOCHighWarnMFOP_Rx: nv-require-com-spec{init-value=Value:0, variable=NePWDR_Cnt_SOCHighWarnMFOP}, required-interface=NePWDR_Cnt_SOCHighWarnMFOP
    provide port NePWDR_Cnt_SOCHighFailureMFOP: nv-provide-com-spec{ram-block-init-value=Value:0, rom-block-init-value=Value:0, variable=NePWDR_Cnt_SOCHighFailureMFOP}, provided-interface=NePWDR_Cnt_SOCHighFailureMFOP
    require port NePWDR_Cnt_SOCHighFailureMFOP_Rx: nv-require-com-spec{init-value=Value:0, variable=NePWDR_Cnt_SOCHighFailureMFOP}, required-interface=NePWDR_Cnt_SOCHighFailureMFOP
    provide port NePWDR_Cnt_MsmtchLowFOP: nv-provide-com-spec{ram-block-init-value=Value:0, rom-block-init-value=Value:0, variable=NePWDR_Cnt_MsmtchLowFOP}, provided-interface=NePWDR_Cnt_MsmtchLowFOP
    require port NePWDR_Cnt_MsmtchLowFOP_Rx: nv-require-com-spec{init-value=Value:0, variable=NePWDR_Cnt_MsmtchLowFOP}, required-interface=NePWDR_Cnt_MsmtchLowFOP
    provide port NePWDR_Cnt_HVUnderVoltWarnMSOF: nv-provide-com-spec{ram-block-init-value=Value:65535, rom-block-init-value=Value:65535, variable=NePWDR_Cnt_HVUnderVoltWarnMSOF}, provided-interface=NePWDR_Cnt_HVUnderVoltWarnMSOF
    require port NePWDR_Cnt_HVUnderVoltWarnMSOF_Rx: nv-require-com-spec{init-value=Value:65535, variable=NePWDR_Cnt_HVUnderVoltWarnMSOF}, required-interface=NePWDR_Cnt_HVUnderVoltWarnMSOF
    provide port NeTHDR_Cnt_AGS_Perf_MFOP: nv-provide-com-spec{ram-block-init-value=Value:0, rom-block-init-value=Value:0, variable=NeTHDR_Cnt_AGS_Perf_MFOP}, provided-interface=NeTHDR_Cnt_AGS_Perf_MFOP
    require port NeTHDR_Cnt_AGS_Perf_MFOP_Rx: nv-require-com-spec{init-value=Value:0, variable=NeTHDR_Cnt_AGS_Perf_MFOP}, required-interface=NeTHDR_Cnt_AGS_Perf_MFOP
    provide port NeTHDR_Cnt_EEXV_Out_MFOP: nv-provide-com-spec{ram-block-init-value=Value:0, rom-block-init-value=Value:0, variable=NeTHDR_Cnt_EEXV_Out_MFOP}, provided-interface=NeTHDR_Cnt_EEXV_Out_MFOP
    require port NeTHDR_Cnt_EEXV_Out_MFOP_Rx: nv-require-com-spec{init-value=Value:0, variable=NeTHDR_Cnt_EEXV_Out_MFOP}, required-interface=NeTHDR_Cnt_EEXV_Out_MFOP
    provide port NeTHDR_Cnt_ECH_outTmpSns_MFOP: nv-provide-com-spec{ram-block-init-value=Value:0, rom-block-init-value=Value:0, variable=NeTHDR_Cnt_ECH_outTmpSns_MFOP}, provided-interface=NeTHDR_Cnt_ECH_outTmpSns_MFOP
    require port NeTHDR_Cnt_ECH_outTmpSns_MFOP_Rx: nv-require-com-spec{init-value=Value:0, variable=NeTHDR_Cnt_ECH_outTmpSns_MFOP}, required-interface=NeTHDR_Cnt_ECH_outTmpSns_MFOP
    provide port NeTHDR_Cnt_ECHTIS_MFOP: nv-provide-com-spec{ram-block-init-value=Value:0, rom-block-init-value=Value:0, variable=NeTHDR_Cnt_ECHTIS_MFOP}, provided-interface=NeTHDR_Cnt_ECHTIS_MFOP
    require port NeTHDR_Cnt_ECHTIS_MFOP_Rx: nv-require-com-spec{init-value=Value:0, variable=NeTHDR_Cnt_ECHTIS_MFOP}, required-interface=NeTHDR_Cnt_ECHTIS_MFOP
    provide port NePWDR_Cnt_HVUnderVoltWarnMFOP: nv-provide-com-spec{ram-block-init-value=Value:0, rom-block-init-value=Value:0, variable=NePWDR_Cnt_HVUnderVoltWarnMFOP}, provided-interface=NePWDR_Cnt_HVUnderVoltWarnMFOP
    require port NePWDR_Cnt_HVUnderVoltWarnMFOP_Rx: nv-require-com-spec{init-value=Value:0, variable=NePWDR_Cnt_HVUnderVoltWarnMFOP}, required-interface=NePWDR_Cnt_HVUnderVoltWarnMFOP
    provide port NePMDD_Cnt_RunHiMaxFOP: nv-provide-com-spec{ram-block-init-value=Value:0, rom-block-init-value=Value:0, variable=NePMDD_Cnt_RunHiMaxFOP}, provided-interface=NePMDD_Cnt_RunHiMaxFOP
    require port NePMDD_Cnt_RunHiMaxFOP_Rx: nv-require-com-spec{init-value=Value:0, variable=NePMDD_Cnt_RunHiMaxFOP}, required-interface=NePMDD_Cnt_RunHiMaxFOP
    provide port NeCPDR_Cnt_LTAP_FunPer_MFOP: nv-provide-com-spec{ram-block-init-value=Value:0, rom-block-init-value=Value:0, variable=NeCPDR_Cnt_LTAP_FunPer_MFOP}, provided-interface=NeCPDR_Cnt_LTAP_FunPer_MFOP
    require port NeCPDR_Cnt_LTAP_FunPer_MFOP_Rx: nv-require-com-spec{init-value=Value:0, variable=NeCPDR_Cnt_LTAP_FunPer_MFOP}, required-interface=NeCPDR_Cnt_LTAP_FunPer_MFOP
    provide port NeCSVD_Cnt_RearAxleRatlFlt_MFOP: nv-provide-com-spec{ram-block-init-value=Value:0, rom-block-init-value=Value:0, variable=NeCSVD_Cnt_RearAxleRatlFlt_MFOP}, provided-interface=NeCSVD_Cnt_RearAxleRatlFlt_MFOP
    require port NeCSVD_Cnt_RearAxleRatlFlt_MFOP_Rx: nv-require-com-spec{init-value=Value:0, variable=NeCSVD_Cnt_RearAxleRatlFlt_MFOP}, required-interface=NeCSVD_Cnt_RearAxleRatlFlt_MFOP
    provide port NeCSVD_Cnt_FrontAxleRatlFlt_MFOP: nv-provide-com-spec{ram-block-init-value=Value:0, rom-block-init-value=Value:0, variable=NeCSVD_Cnt_FrontAxleRatlFlt_MFOP}, provided-interface=NeCSVD_Cnt_FrontAxleRatlFlt_MFOP
    require port NeCSVD_Cnt_FrontAxleRatlFlt_MFOP_Rx: nv-require-com-spec{init-value=Value:0, variable=NeCSVD_Cnt_FrontAxleRatlFlt_MFOP}, required-interface=NeCSVD_Cnt_FrontAxleRatlFlt_MFOP
    provide port NeCPDR_Cnt_LTPP_FunPer_MFOP: nv-provide-com-spec{ram-block-init-value=Value:0, rom-block-init-value=Value:0, variable=NeCPDR_Cnt_LTPP_FunPer_MFOP}, provided-interface=NeCPDR_Cnt_LTPP_FunPer_MFOP
    require port NeCPDR_Cnt_LTPP_FunPer_MFOP_Rx: nv-require-com-spec{init-value=Value:0, variable=NeCPDR_Cnt_LTPP_FunPer_MFOP}, required-interface=NeCPDR_Cnt_LTPP_FunPer_MFOP
    provide port NeCPDR_Cnt_LTPP_FunDryRun_MFOP: nv-provide-com-spec{ram-block-init-value=Value:0, rom-block-init-value=Value:0, variable=NeCPDR_Cnt_LTPP_FunDryRun_MFOP}, provided-interface=NeCPDR_Cnt_LTPP_FunDryRun_MFOP
    require port NeCPDR_Cnt_LTPP_FunDryRun_MFOP_Rx: nv-require-com-spec{init-value=Value:0, variable=NeCPDR_Cnt_LTPP_FunDryRun_MFOP}, required-interface=NeCPDR_Cnt_LTPP_FunDryRun_MFOP
    provide port NeCPDR_Cnt_LTPP2_FunPer_MFOP: nv-provide-com-spec{ram-block-init-value=Value:0, rom-block-init-value=Value:0, variable=NeCPDR_Cnt_LTPP2_FunPer_MFOP}, provided-interface=NeCPDR_Cnt_LTPP2_FunPer_MFOP
    require port NeCPDR_Cnt_LTPP2_FunPer_MFOP_Rx: nv-require-com-spec{init-value=Value:0, variable=NeCPDR_Cnt_LTPP2_FunPer_MFOP}, required-interface=NeCPDR_Cnt_LTPP2_FunPer_MFOP
    provide port NeCPDR_Cnt_LTPP2_FunDryRun_MFOP: nv-provide-com-spec{ram-block-init-value=Value:0, rom-block-init-value=Value:0, variable=NeCPDR_Cnt_LTPP2_FunDryRun_MFOP}, provided-interface=NeCPDR_Cnt_LTPP2_FunDryRun_MFOP
    require port NeCPDR_Cnt_LTPP2_FunDryRun_MFOP_Rx: nv-require-com-spec{init-value=Value:0, variable=NeCPDR_Cnt_LTPP2_FunDryRun_MFOP}, required-interface=NeCPDR_Cnt_LTPP2_FunDryRun_MFOP
    provide port NeCPDR_Cnt_LTAP_FunDryRun_MFOP: nv-provide-com-spec{ram-block-init-value=Value:0, rom-block-init-value=Value:0, variable=NeCPDR_Cnt_LTAP_FunDryRun_MFOP}, provided-interface=NeCPDR_Cnt_LTAP_FunDryRun_MFOP
    require port NeCPDR_Cnt_LTAP_FunDryRun_MFOP_Rx: nv-require-com-spec{init-value=Value:0, variable=NeCPDR_Cnt_LTAP_FunDryRun_MFOP}, required-interface=NeCPDR_Cnt_LTAP_FunDryRun_MFOP
    provide port NeDMIR_e_DriveStyleSts: nv-provide-com-spec{ram-block-init-value=Value:0, rom-block-init-value=Value:0, variable=NeDMIR_e_DriveStyleSts}, provided-interface=NeDMIR_e_DriveStyleSts
    require port NeDMIR_e_DriveStyleSts_Rx: nv-require-com-spec{init-value=Value:0, variable=NeDMIR_e_DriveStyleSts}, required-interface=NeDMIR_e_DriveStyleSts
    provide port NeCPDR_Cnt_HTAP_FunPer_MFOP: nv-provide-com-spec{ram-block-init-value=Value:0, rom-block-init-value=Value:0, variable=NeCPDR_Cnt_HTAP_FunPer_MFOP}, provided-interface=NeCPDR_Cnt_HTAP_FunPer_MFOP
    require port NeCPDR_Cnt_HTAP_FunPer_MFOP_Rx: nv-require-com-spec{init-value=Value:0, variable=NeCPDR_Cnt_HTAP_FunPer_MFOP}, required-interface=NeCPDR_Cnt_HTAP_FunPer_MFOP
    provide port NeCPDR_Cnt_EOPB_FunPer_MFOP: nv-provide-com-spec{ram-block-init-value=Value:0, rom-block-init-value=Value:0, variable=NeCPDR_Cnt_EOPB_FunPer_MFOP}, provided-interface=NeCPDR_Cnt_EOPB_FunPer_MFOP
    require port NeCPDR_Cnt_EOPB_FunPer_MFOP_Rx: nv-require-com-spec{init-value=Value:0, variable=NeCPDR_Cnt_EOPB_FunPer_MFOP}, required-interface=NeCPDR_Cnt_EOPB_FunPer_MFOP
    provide port NeCPDR_Cnt_EOPB_FunDryRun_MFOP: nv-provide-com-spec{ram-block-init-value=Value:0, rom-block-init-value=Value:0, variable=NeCPDR_Cnt_EOPB_FunDryRun_MFOP}, provided-interface=NeCPDR_Cnt_EOPB_FunDryRun_MFOP
    require port NeCPDR_Cnt_EOPB_FunDryRun_MFOP_Rx: nv-require-com-spec{init-value=Value:0, variable=NeCPDR_Cnt_EOPB_FunDryRun_MFOP}, required-interface=NeCPDR_Cnt_EOPB_FunDryRun_MFOP
    provide port NeCPDR_Cnt_EOPA_FunPer_MFOP: nv-provide-com-spec{ram-block-init-value=Value:0, rom-block-init-value=Value:0, variable=NeCPDR_Cnt_EOPA_FunPer_MFOP}, provided-interface=NeCPDR_Cnt_EOPA_FunPer_MFOP
    require port NeCPDR_Cnt_EOPA_FunPer_MFOP_Rx: nv-require-com-spec{init-value=Value:0, variable=NeCPDR_Cnt_EOPA_FunPer_MFOP}, required-interface=NeCPDR_Cnt_EOPA_FunPer_MFOP
    provide port NeCPDR_Cnt_EOPA_FunDryRun_MFOP: nv-provide-com-spec{ram-block-init-value=Value:0, rom-block-init-value=Value:0, variable=NeCPDR_Cnt_EOPA_FunDryRun_MFOP}, provided-interface=NeCPDR_Cnt_EOPA_FunDryRun_MFOP
    require port NeCPDR_Cnt_EOPA_FunDryRun_MFOP_Rx: nv-require-com-spec{init-value=Value:0, variable=NeCPDR_Cnt_EOPA_FunDryRun_MFOP}, required-interface=NeCPDR_Cnt_EOPA_FunDryRun_MFOP
    provide port NeCDMR_Cnt_PwrOutletPanelMod2Perf_MFOP: nv-provide-com-spec{ram-block-init-value=Value:0, rom-block-init-value=Value:0, variable=NeCDMR_Cnt_PwrOutletPanelMod2Perf_MFOP}, provided-interface=NeCDMR_Cnt_PwrOutletPanelMod2Perf_MFOP
    require port NeCDMR_Cnt_PwrOutletPanelMod2Perf_MFOP_Rx: nv-require-com-spec{init-value=Value:0, variable=NeCDMR_Cnt_PwrOutletPanelMod2Perf_MFOP}, required-interface=NeCDMR_Cnt_PwrOutletPanelMod2Perf_MFOP
    provide port NeCDMR_Cnt_PwrOutletPanelMod2LmpCntrl_MFOP: nv-provide-com-spec{ram-block-init-value=Value:0, rom-block-init-value=Value:0, variable=NeCDMR_Cnt_PwrOutletPanelMod2LmpCntrl_MFOP}, provided-interface=NeCDMR_Cnt_PwrOutletPanelMod2LmpCntrl_MFOP
    require port NeCDMR_Cnt_PwrOutletPanelMod2LmpCntrl_MFOP_Rx: nv-require-com-spec{init-value=Value:0, variable=NeCDMR_Cnt_PwrOutletPanelMod2LmpCntrl_MFOP}, required-interface=NeCDMR_Cnt_PwrOutletPanelMod2LmpCntrl_MFOP
    provide port NeCDMR_Cnt_PwrOutletPanelMod2InACPwrCktPerf_MFOP: nv-provide-com-spec{ram-block-init-value=Value:0, rom-block-init-value=Value:0, variable=NeCDMR_Cnt_PwrOutletPanelMod2InACPwrCktPerf_MFOP}, provided-interface=NeCDMR_Cnt_PwrOutletPanelMod2InACPwrCktPerf_MFOP
    require port NeCDMR_Cnt_PwrOutletPanelMod2InACPwrCktPerf_MFOP_Rx: nv-require-com-spec{init-value=Value:0, variable=NeCDMR_Cnt_PwrOutletPanelMod2InACPwrCktPerf_MFOP}, required-interface=NeCDMR_Cnt_PwrOutletPanelMod2InACPwrCktPerf_MFOP
    provide port NeCDMR_Cnt_PwrOutletPanelMod1Perf_MFOP: nv-provide-com-spec{ram-block-init-value=Value:0, rom-block-init-value=Value:0, variable=NeCDMR_Cnt_PwrOutletPanelMod1Perf_MFOP}, provided-interface=NeCDMR_Cnt_PwrOutletPanelMod1Perf_MFOP
    require port NeCDMR_Cnt_PwrOutletPanelMod1Perf_MFOP_Rx: nv-require-com-spec{init-value=Value:0, variable=NeCDMR_Cnt_PwrOutletPanelMod1Perf_MFOP}, required-interface=NeCDMR_Cnt_PwrOutletPanelMod1Perf_MFOP
    provide port NeDMIR_e_DrvMdArb: nv-provide-com-spec{ram-block-init-value=Value:0, rom-block-init-value=Value:0, variable=NeDMIR_e_DrvMdArb}, provided-interface=NeDMIR_e_DrvMdArb
    require port NeDMIR_e_DrvMdArb_Rx: nv-require-com-spec{init-value=Value:0, variable=NeDMIR_e_DrvMdArb}, required-interface=NeDMIR_e_DrvMdArb
    provide port NeHCDR_Cnt_HVC_Heater_MFOP: nv-provide-com-spec{ram-block-init-value=Value:0, rom-block-init-value=Value:0, variable=NeHCDR_Cnt_HVC_Heater_MFOP}, provided-interface=NeHCDR_Cnt_HVC_Heater_MFOP
    require port NeHCDR_Cnt_HVC_Heater_MFOP_Rx: nv-require-com-spec{init-value=Value:0, variable=NeHCDR_Cnt_HVC_Heater_MFOP}, required-interface=NeHCDR_Cnt_HVC_Heater_MFOP
    provide port NeHSWD_Cnt_SecBnt_Correlation_MFOP: nv-provide-com-spec{ram-block-init-value=Value:0, rom-block-init-value=Value:0, variable=NeHSWD_Cnt_SecBnt_Correlation_MFOP}, provided-interface=NeHSWD_Cnt_SecBnt_Correlation_MFOP
    require port NeHSWD_Cnt_SecBnt_Correlation_MFOP_Rx: nv-require-com-spec{init-value=Value:0, variable=NeHSWD_Cnt_SecBnt_Correlation_MFOP}, required-interface=NeHSWD_Cnt_SecBnt_Correlation_MFOP
    provide port NeHSWD_Cnt_SecBnt_CircuitPerf_MFOP: nv-provide-com-spec{ram-block-init-value=Value:0, rom-block-init-value=Value:0, variable=NeHSWD_Cnt_SecBnt_CircuitPerf_MFOP}, provided-interface=NeHSWD_Cnt_SecBnt_CircuitPerf_MFOP
    require port NeHSWD_Cnt_SecBnt_CircuitPerf_MFOP_Rx: nv-require-com-spec{init-value=Value:0, variable=NeHSWD_Cnt_SecBnt_CircuitPerf_MFOP}, required-interface=NeHSWD_Cnt_SecBnt_CircuitPerf_MFOP
    provide port NeHSWD_Cnt_SecBnt_CircuitLow_MFOP: nv-provide-com-spec{ram-block-init-value=Value:0, rom-block-init-value=Value:0, variable=NeHSWD_Cnt_SecBnt_CircuitLow_MFOP}, provided-interface=NeHSWD_Cnt_SecBnt_CircuitLow_MFOP
    require port NeHSWD_Cnt_SecBnt_CircuitLow_MFOP_Rx: nv-require-com-spec{init-value=Value:0, variable=NeHSWD_Cnt_SecBnt_CircuitLow_MFOP}, required-interface=NeHSWD_Cnt_SecBnt_CircuitLow_MFOP
    provide port NeHSWD_Cnt_SecBnt_CircuitHigh_MFOP: nv-provide-com-spec{ram-block-init-value=Value:0, rom-block-init-value=Value:0, variable=NeHSWD_Cnt_SecBnt_CircuitHigh_MFOP}, provided-interface=NeHSWD_Cnt_SecBnt_CircuitHigh_MFOP
    require port NeHSWD_Cnt_SecBnt_CircuitHigh_MFOP_Rx: nv-require-com-spec{init-value=Value:0, variable=NeHSWD_Cnt_SecBnt_CircuitHigh_MFOP}, required-interface=NeHSWD_Cnt_SecBnt_CircuitHigh_MFOP
    provide port NeHSWD_Cnt_CBC_FaultLow_MFOP: nv-provide-com-spec{ram-block-init-value=Value:0, rom-block-init-value=Value:0, variable=NeHSWD_Cnt_CBC_FaultLow_MFOP}, provided-interface=NeHSWD_Cnt_CBC_FaultLow_MFOP
    require port NeHSWD_Cnt_CBC_FaultLow_MFOP_Rx: nv-require-com-spec{init-value=Value:0, variable=NeHSWD_Cnt_CBC_FaultLow_MFOP}, required-interface=NeHSWD_Cnt_CBC_FaultLow_MFOP
    provide port NeHSWD_Cnt_CBC_FaultHigh_MFOP: nv-provide-com-spec{ram-block-init-value=Value:0, rom-block-init-value=Value:0, variable=NeHSWD_Cnt_CBC_FaultHigh_MFOP}, provided-interface=NeHSWD_Cnt_CBC_FaultHigh_MFOP
    require port NeHSWD_Cnt_CBC_FaultHigh_MFOP_Rx: nv-require-com-spec{init-value=Value:0, variable=NeHSWD_Cnt_CBC_FaultHigh_MFOP}, required-interface=NeHSWD_Cnt_CBC_FaultHigh_MFOP
    provide port NeHCDR_Cnt_HVC_Heater4_MFOP: nv-provide-com-spec{ram-block-init-value=Value:0, rom-block-init-value=Value:0, variable=NeHCDR_Cnt_HVC_Heater4_MFOP}, provided-interface=NeHCDR_Cnt_HVC_Heater4_MFOP
    require port NeHCDR_Cnt_HVC_Heater4_MFOP_Rx: nv-require-com-spec{init-value=Value:0, variable=NeHCDR_Cnt_HVC_Heater4_MFOP}, required-interface=NeHCDR_Cnt_HVC_Heater4_MFOP
    provide port NeHCDR_Cnt_HVC_Heater3_MFOP: nv-provide-com-spec{ram-block-init-value=Value:0, rom-block-init-value=Value:0, variable=NeHCDR_Cnt_HVC_Heater3_MFOP}, provided-interface=NeHCDR_Cnt_HVC_Heater3_MFOP
    require port NeHCDR_Cnt_HVC_Heater3_MFOP_Rx: nv-require-com-spec{init-value=Value:0, variable=NeHCDR_Cnt_HVC_Heater3_MFOP}, required-interface=NeHCDR_Cnt_HVC_Heater3_MFOP
    provide port NeHCDR_Cnt_HVC_Heater2_MFOP: nv-provide-com-spec{ram-block-init-value=Value:0, rom-block-init-value=Value:0, variable=NeHCDR_Cnt_HVC_Heater2_MFOP}, provided-interface=NeHCDR_Cnt_HVC_Heater2_MFOP
    require port NeHCDR_Cnt_HVC_Heater2_MFOP_Rx: nv-require-com-spec{init-value=Value:0, variable=NeHCDR_Cnt_HVC_Heater2_MFOP}, required-interface=NeHCDR_Cnt_HVC_Heater2_MFOP
    provide port NeHCDR_Cnt_EACPref_MFOP: nv-provide-com-spec{ram-block-init-value=Value:0, rom-block-init-value=Value:0, variable=NeHCDR_Cnt_EACPref_MFOP}, provided-interface=NeHCDR_Cnt_EACPref_MFOP
    require port NeHCDR_Cnt_EACPref_MFOP_Rx: nv-require-com-spec{init-value=Value:0, variable=NeHCDR_Cnt_EACPref_MFOP}, required-interface=NeHCDR_Cnt_EACPref_MFOP
    provide port NeGENR_Cnt_InPlantAPMOff: nv-provide-com-spec{ram-block-init-value=Value:0, rom-block-init-value=Value:0, variable=NeGENR_Cnt_InPlantAPMOff}, provided-interface=NeGENR_Cnt_InPlantAPMOff
    require port NeGENR_Cnt_InPlantAPMOff_Rx: nv-require-com-spec{init-value=Value:0, variable=NeGENR_Cnt_InPlantAPMOff}, required-interface=NeGENR_Cnt_InPlantAPMOff
    provide port NeCDMR_Cnt_PwrOutletPanelMod1LmpCntrl_MFOP: nv-provide-com-spec{ram-block-init-value=Value:0, rom-block-init-value=Value:0, variable=NeCDMR_Cnt_PwrOutletPanelMod1LmpCntrl_MFOP}, provided-interface=NeCDMR_Cnt_PwrOutletPanelMod1LmpCntrl_MFOP
    require port NeCDMR_Cnt_PwrOutletPanelMod1LmpCntrl_MFOP_Rx: nv-require-com-spec{init-value=Value:0, variable=NeCDMR_Cnt_PwrOutletPanelMod1LmpCntrl_MFOP}, required-interface=NeCDMR_Cnt_PwrOutletPanelMod1LmpCntrl_MFOP
    provide port NeCDMR_Cnt_PwrOutletPanelMod1InACPwrCktPerf_MFOP: nv-provide-com-spec{ram-block-init-value=Value:0, rom-block-init-value=Value:0, variable=NeCDMR_Cnt_PwrOutletPanelMod1InACPwrCktPerf_MFOP}, provided-interface=NeCDMR_Cnt_PwrOutletPanelMod1InACPwrCktPerf_MFOP
    require port NeCDMR_Cnt_PwrOutletPanelMod1InACPwrCktPerf_MFOP_Rx: nv-require-com-spec{init-value=Value:0, variable=NeCDMR_Cnt_PwrOutletPanelMod1InACPwrCktPerf_MFOP}, required-interface=NeCDMR_Cnt_PwrOutletPanelMod1InACPwrCktPerf_MFOP
    provide port NeCDMR_Cnt_InletSensor_MFOP: nv-provide-com-spec{ram-block-init-value=Value:0, rom-block-init-value=Value:0, variable=NeCDMR_Cnt_InletSensor_MFOP}, provided-interface=NeCDMR_Cnt_InletSensor_MFOP
    require port NeCDMR_Cnt_InletSensor_MFOP_Rx: nv-require-com-spec{init-value=Value:0, variable=NeCDMR_Cnt_InletSensor_MFOP}, required-interface=NeCDMR_Cnt_InletSensor_MFOP
    provide port NeAATR_Cnt_SCP_DCPstvTemp_LoFlt_MFOP: nv-provide-com-spec{ram-block-init-value=Value:0, rom-block-init-value=Value:0, variable=NeAATR_Cnt_SCP_DCPstvTemp_LoFlt_MFOP}, provided-interface=NeAATR_Cnt_SCP_DCPstvTemp_LoFlt_MFOP
    require port NeAATR_Cnt_SCP_DCPstvTemp_LoFlt_MFOP_Rx: nv-require-com-spec{init-value=Value:0, variable=NeAATR_Cnt_SCP_DCPstvTemp_LoFlt_MFOP}, required-interface=NeAATR_Cnt_SCP_DCPstvTemp_LoFlt_MFOP
    provide port NeBPCR_Cnt_PWMCntctrStMFOP: nv-provide-com-spec{ram-block-init-value=Value:0, rom-block-init-value=Value:0, variable=NeBPCR_Cnt_PWMCntctrStMFOP}, provided-interface=NeBPCR_Cnt_PWMCntctrStMFOP
    require port NeBPCR_Cnt_PWMCntctrStMFOP_Rx: nv-require-com-spec{init-value=Value:0, variable=NeBPCR_Cnt_PWMCntctrStMFOP}, required-interface=NeBPCR_Cnt_PWMCntctrStMFOP
    provide port NeADIR_Cnt_WEDMechFailure_MFOP: nv-provide-com-spec{ram-block-init-value=Value:0, rom-block-init-value=Value:0, variable=NeADIR_Cnt_WEDMechFailure_MFOP}, provided-interface=NeADIR_Cnt_WEDMechFailure_MFOP
    require port NeADIR_Cnt_WEDMechFailure_MFOP_Rx: nv-require-com-spec{init-value=Value:0, variable=NeADIR_Cnt_WEDMechFailure_MFOP}, required-interface=NeADIR_Cnt_WEDMechFailure_MFOP
    provide port NeAATR_Cnt_SCP_InletTemp_PerfFlt_MFOP: nv-provide-com-spec{ram-block-init-value=Value:0, rom-block-init-value=Value:0, variable=NeAATR_Cnt_SCP_InletTemp_PerfFlt_MFOP}, provided-interface=NeAATR_Cnt_SCP_InletTemp_PerfFlt_MFOP
    require port NeAATR_Cnt_SCP_InletTemp_PerfFlt_MFOP_Rx: nv-require-com-spec{init-value=Value:0, variable=NeAATR_Cnt_SCP_InletTemp_PerfFlt_MFOP}, required-interface=NeAATR_Cnt_SCP_InletTemp_PerfFlt_MFOP
    provide port NeAATR_Cnt_SCP_InletTemp_LoFlt_MFOP: nv-provide-com-spec{ram-block-init-value=Value:0, rom-block-init-value=Value:0, variable=NeAATR_Cnt_SCP_InletTemp_LoFlt_MFOP}, provided-interface=NeAATR_Cnt_SCP_InletTemp_LoFlt_MFOP
    require port NeAATR_Cnt_SCP_InletTemp_LoFlt_MFOP_Rx: nv-require-com-spec{init-value=Value:0, variable=NeAATR_Cnt_SCP_InletTemp_LoFlt_MFOP}, required-interface=NeAATR_Cnt_SCP_InletTemp_LoFlt_MFOP
    provide port NeAATR_Cnt_SCP_InletTemp_HiFlt_MFOP: nv-provide-com-spec{ram-block-init-value=Value:0, rom-block-init-value=Value:0, variable=NeAATR_Cnt_SCP_InletTemp_HiFlt_MFOP}, provided-interface=NeAATR_Cnt_SCP_InletTemp_HiFlt_MFOP
    require port NeAATR_Cnt_SCP_InletTemp_HiFlt_MFOP_Rx: nv-require-com-spec{init-value=Value:0, variable=NeAATR_Cnt_SCP_InletTemp_HiFlt_MFOP}, required-interface=NeAATR_Cnt_SCP_InletTemp_HiFlt_MFOP
    provide port NeAATR_Cnt_SCP_InletTemp_Flt_MFOP: nv-provide-com-spec{ram-block-init-value=Value:0, rom-block-init-value=Value:0, variable=NeAATR_Cnt_SCP_InletTemp_Flt_MFOP}, provided-interface=NeAATR_Cnt_SCP_InletTemp_Flt_MFOP
    require port NeAATR_Cnt_SCP_InletTemp_Flt_MFOP_Rx: nv-require-com-spec{init-value=Value:0, variable=NeAATR_Cnt_SCP_InletTemp_Flt_MFOP}, required-interface=NeAATR_Cnt_SCP_InletTemp_Flt_MFOP
    provide port NeAATR_Cnt_SCP_DCPstvTemp_PerfFlt_MFOP: nv-provide-com-spec{ram-block-init-value=Value:0, rom-block-init-value=Value:0, variable=NeAATR_Cnt_SCP_DCPstvTemp_PerfFlt_MFOP}, provided-interface=NeAATR_Cnt_SCP_DCPstvTemp_PerfFlt_MFOP
    require port NeAATR_Cnt_SCP_DCPstvTemp_PerfFlt_MFOP_Rx: nv-require-com-spec{init-value=Value:0, variable=NeAATR_Cnt_SCP_DCPstvTemp_PerfFlt_MFOP}, required-interface=NeAATR_Cnt_SCP_DCPstvTemp_PerfFlt_MFOP
    provide port NeAATR_Cnt_SCP_DCPstvTemp_Flt_MFOP: nv-provide-com-spec{ram-block-init-value=Value:0, rom-block-init-value=Value:0, variable=NeAATR_Cnt_SCP_DCPstvTemp_Flt_MFOP}, provided-interface=NeAATR_Cnt_SCP_DCPstvTemp_Flt_MFOP
    require port NeAATR_Cnt_SCP_DCPstvTemp_Flt_MFOP_Rx: nv-require-com-spec{init-value=Value:0, variable=NeAATR_Cnt_SCP_DCPstvTemp_Flt_MFOP}, required-interface=NeAATR_Cnt_SCP_DCPstvTemp_Flt_MFOP
    provide port NeCDMR_Cnt_DTCShortName6_MFOP: nv-provide-com-spec{ram-block-init-value=Value:0, rom-block-init-value=Value:0, variable=NeCDMR_Cnt_DTCShortName6_MFOP}, provided-interface=NeCDMR_Cnt_DTCShortName6_MFOP
    require port NeCDMR_Cnt_DTCShortName6_MFOP_Rx: nv-require-com-spec{init-value=Value:0, variable=NeCDMR_Cnt_DTCShortName6_MFOP}, required-interface=NeCDMR_Cnt_DTCShortName6_MFOP
    provide port NeAATR_Cnt_SCP_DCNegtvTemp_PerfFlt_MFOP: nv-provide-com-spec{ram-block-init-value=Value:0, rom-block-init-value=Value:0, variable=NeAATR_Cnt_SCP_DCNegtvTemp_PerfFlt_MFOP}, provided-interface=NeAATR_Cnt_SCP_DCNegtvTemp_PerfFlt_MFOP
    require port NeAATR_Cnt_SCP_DCNegtvTemp_PerfFlt_MFOP_Rx: nv-require-com-spec{init-value=Value:0, variable=NeAATR_Cnt_SCP_DCNegtvTemp_PerfFlt_MFOP}, required-interface=NeAATR_Cnt_SCP_DCNegtvTemp_PerfFlt_MFOP
    provide port NeAATR_Cnt_SCP_DCNegtvTemp_LoFlt_MFOP: nv-provide-com-spec{ram-block-init-value=Value:0, rom-block-init-value=Value:0, variable=NeAATR_Cnt_SCP_DCNegtvTemp_LoFlt_MFOP}, provided-interface=NeAATR_Cnt_SCP_DCNegtvTemp_LoFlt_MFOP
    require port NeAATR_Cnt_SCP_DCNegtvTemp_LoFlt_MFOP_Rx: nv-require-com-spec{init-value=Value:0, variable=NeAATR_Cnt_SCP_DCNegtvTemp_LoFlt_MFOP}, required-interface=NeAATR_Cnt_SCP_DCNegtvTemp_LoFlt_MFOP
    provide port NeAATR_Cnt_SCP_DCNegtvTemp_HiFlt_MFOP: nv-provide-com-spec{ram-block-init-value=Value:0, rom-block-init-value=Value:0, variable=NeAATR_Cnt_SCP_DCNegtvTemp_HiFlt_MFOP}, provided-interface=NeAATR_Cnt_SCP_DCNegtvTemp_HiFlt_MFOP
    require port NeAATR_Cnt_SCP_DCNegtvTemp_HiFlt_MFOP_Rx: nv-require-com-spec{init-value=Value:0, variable=NeAATR_Cnt_SCP_DCNegtvTemp_HiFlt_MFOP}, required-interface=NeAATR_Cnt_SCP_DCNegtvTemp_HiFlt_MFOP
    provide port NeAATR_Cnt_SCP_DCNegtvTemp_Flt_MFOP: nv-provide-com-spec{ram-block-init-value=Value:0, rom-block-init-value=Value:0, variable=NeAATR_Cnt_SCP_DCNegtvTemp_Flt_MFOP}, provided-interface=NeAATR_Cnt_SCP_DCNegtvTemp_Flt_MFOP
    require port NeAATR_Cnt_SCP_DCNegtvTemp_Flt_MFOP_Rx: nv-require-com-spec{init-value=Value:0, variable=NeAATR_Cnt_SCP_DCNegtvTemp_Flt_MFOP}, required-interface=NeAATR_Cnt_SCP_DCNegtvTemp_Flt_MFOP
    provide port NeAATR_Cnt_ECM_IntakeTemp_PerfFlt_MFOP: nv-provide-com-spec{ram-block-init-value=Value:0, rom-block-init-value=Value:0, variable=NeAATR_Cnt_ECM_IntakeTemp_PerfFlt_MFOP}, provided-interface=NeAATR_Cnt_ECM_IntakeTemp_PerfFlt_MFOP
    require port NeAATR_Cnt_ECM_IntakeTemp_PerfFlt_MFOP_Rx: nv-require-com-spec{init-value=Value:0, variable=NeAATR_Cnt_ECM_IntakeTemp_PerfFlt_MFOP}, required-interface=NeAATR_Cnt_ECM_IntakeTemp_PerfFlt_MFOP
    provide port NeAATR_Cnt_DCPstvTemp_HiFlt_MFOP: nv-provide-com-spec{ram-block-init-value=Value:0, rom-block-init-value=Value:0, variable=NeAATR_Cnt_DCPstvTemp_HiFlt_MFOP}, provided-interface=NeAATR_Cnt_DCPstvTemp_HiFlt_MFOP
    require port NeAATR_Cnt_DCPstvTemp_HiFlt_MFOP_Rx: nv-require-com-spec{init-value=Value:0, variable=NeAATR_Cnt_DCPstvTemp_HiFlt_MFOP}, required-interface=NeAATR_Cnt_DCPstvTemp_HiFlt_MFOP
    provide port NeAATR_Cnt_AmbAirVolt_LoFlt_MFOP: nv-provide-com-spec{ram-block-init-value=Value:0, rom-block-init-value=Value:0, variable=NeAATR_Cnt_AmbAirVolt_LoFlt_MFOP}, provided-interface=NeAATR_Cnt_AmbAirVolt_LoFlt_MFOP
    require port NeAATR_Cnt_AmbAirVolt_LoFlt_MFOP_Rx: nv-require-com-spec{init-value=Value:0, variable=NeAATR_Cnt_AmbAirVolt_LoFlt_MFOP}, required-interface=NeAATR_Cnt_AmbAirVolt_LoFlt_MFOP
    provide port NeAATR_Cnt_AmbAirVolt_HiFlt_MFOP: nv-provide-com-spec{ram-block-init-value=Value:0, rom-block-init-value=Value:0, variable=NeAATR_Cnt_AmbAirVolt_HiFlt_MFOP}, provided-interface=NeAATR_Cnt_AmbAirVolt_HiFlt_MFOP
    require port NeAATR_Cnt_AmbAirVolt_HiFlt_MFOP_Rx: nv-require-com-spec{init-value=Value:0, variable=NeAATR_Cnt_AmbAirVolt_HiFlt_MFOP}, required-interface=NeAATR_Cnt_AmbAirVolt_HiFlt_MFOP
    provide port NeAATR_Cnt_AmbAirTemp_PerfFlt_MFOP: nv-provide-com-spec{ram-block-init-value=Value:0, rom-block-init-value=Value:0, variable=NeAATR_Cnt_AmbAirTemp_PerfFlt_MFOP}, provided-interface=NeAATR_Cnt_AmbAirTemp_PerfFlt_MFOP
    require port NeAATR_Cnt_AmbAirTemp_PerfFlt_MFOP_Rx: nv-require-com-spec{init-value=Value:0, variable=NeAATR_Cnt_AmbAirTemp_PerfFlt_MFOP}, required-interface=NeAATR_Cnt_AmbAirTemp_PerfFlt_MFOP
    provide port NeCDMR_Cnt_ChrgPortUnlock_MFOP: nv-provide-com-spec{ram-block-init-value=Value:0, rom-block-init-value=Value:0, variable=NeCDMR_Cnt_ChrgPortUnlock_MFOP}, provided-interface=NeCDMR_Cnt_ChrgPortUnlock_MFOP
    require port NeCDMR_Cnt_ChrgPortUnlock_MFOP_Rx: nv-require-com-spec{init-value=Value:0, variable=NeCDMR_Cnt_ChrgPortUnlock_MFOP}, required-interface=NeCDMR_Cnt_ChrgPortUnlock_MFOP
    provide port NeCDMR_Cnt_ChrgPortRlyActCkt_MFOP: nv-provide-com-spec{ram-block-init-value=Value:0, rom-block-init-value=Value:0, variable=NeCDMR_Cnt_ChrgPortRlyActCkt_MFOP}, provided-interface=NeCDMR_Cnt_ChrgPortRlyActCkt_MFOP
    require port NeCDMR_Cnt_ChrgPortRlyActCkt_MFOP_Rx: nv-require-com-spec{init-value=Value:0, variable=NeCDMR_Cnt_ChrgPortRlyActCkt_MFOP}, required-interface=NeCDMR_Cnt_ChrgPortRlyActCkt_MFOP
    provide port NeCDMR_Cnt_ChrgPortLock_MFOP: nv-provide-com-spec{ram-block-init-value=Value:0, rom-block-init-value=Value:0, variable=NeCDMR_Cnt_ChrgPortLock_MFOP}, provided-interface=NeCDMR_Cnt_ChrgPortLock_MFOP
    require port NeCDMR_Cnt_ChrgPortLock_MFOP_Rx: nv-require-com-spec{init-value=Value:0, variable=NeCDMR_Cnt_ChrgPortLock_MFOP}, required-interface=NeCDMR_Cnt_ChrgPortLock_MFOP
    provide port NeCDMR_Cnt_ChgPrtLckFailLMFOP: nv-provide-com-spec{ram-block-init-value=Value:0, rom-block-init-value=Value:0, variable=NeCDMR_Cnt_ChgPrtLckFailLMFOP}, provided-interface=NeCDMR_Cnt_ChgPrtLckFailLMFOP
    require port NeCDMR_Cnt_ChgPrtLckFailLMFOP_Rx: nv-require-com-spec{init-value=Value:0, variable=NeCDMR_Cnt_ChgPrtLckFailLMFOP}, required-interface=NeCDMR_Cnt_ChgPrtLckFailLMFOP
    provide port NeCDMR_Cnt_ChgPrtLckFailHMFOP: nv-provide-com-spec{ram-block-init-value=Value:0, rom-block-init-value=Value:0, variable=NeCDMR_Cnt_ChgPrtLckFailHMFOP}, provided-interface=NeCDMR_Cnt_ChgPrtLckFailHMFOP
    require port NeCDMR_Cnt_ChgPrtLckFailHMFOP_Rx: nv-require-com-spec{init-value=Value:0, variable=NeCDMR_Cnt_ChgPrtLckFailHMFOP}, required-interface=NeCDMR_Cnt_ChgPrtLckFailHMFOP
    provide port NeCDMR_Cnt_CPIMInternal_MFOP: nv-provide-com-spec{ram-block-init-value=Value:0, rom-block-init-value=Value:0, variable=NeCDMR_Cnt_CPIMInternal_MFOP}, provided-interface=NeCDMR_Cnt_CPIMInternal_MFOP
    require port NeCDMR_Cnt_CPIMInternal_MFOP_Rx: nv-require-com-spec{init-value=Value:0, variable=NeCDMR_Cnt_CPIMInternal_MFOP}, required-interface=NeCDMR_Cnt_CPIMInternal_MFOP
    provide port NeCDMR_Cnt_BCIMInternal_MFOP: nv-provide-com-spec{ram-block-init-value=Value:0, rom-block-init-value=Value:0, variable=NeCDMR_Cnt_BCIMInternal_MFOP}, provided-interface=NeCDMR_Cnt_BCIMInternal_MFOP
    require port NeCDMR_Cnt_BCIMInternal_MFOP_Rx: nv-require-com-spec{init-value=Value:0, variable=NeCDMR_Cnt_BCIMInternal_MFOP}, required-interface=NeCDMR_Cnt_BCIMInternal_MFOP
    provide port NeCCTR_Cnt_SpdCntrlSw1_MFOP: nv-provide-com-spec{ram-block-init-value=Value:0, rom-block-init-value=Value:0, variable=NeCCTR_Cnt_SpdCntrlSw1_MFOP}, provided-interface=NeCCTR_Cnt_SpdCntrlSw1_MFOP
    require port NeCCTR_Cnt_SpdCntrlSw1_MFOP_Rx: nv-require-com-spec{init-value=Value:0, variable=NeCCTR_Cnt_SpdCntrlSw1_MFOP}, required-interface=NeCCTR_Cnt_SpdCntrlSw1_MFOP
    provide port NeBTQD_Cnt_ESPSignalDiag_MFOP: nv-provide-com-spec{ram-block-init-value=Value:0, rom-block-init-value=Value:0, variable=NeBTQD_Cnt_ESPSignalDiag_MFOP}, provided-interface=NeBTQD_Cnt_ESPSignalDiag_MFOP
    require port NeBTQD_Cnt_ESPSignalDiag_MFOP_Rx: nv-require-com-spec{init-value=Value:0, variable=NeBTQD_Cnt_ESPSignalDiag_MFOP}, required-interface=NeBTQD_Cnt_ESPSignalDiag_MFOP
    provide port NeBRDR_Cnt_LTAP_MFOP: nv-provide-com-spec{ram-block-init-value=Value:0, rom-block-init-value=Value:0, variable=NeBRDR_Cnt_LTAP_MFOP}, provided-interface=NeBRDR_Cnt_LTAP_MFOP
    require port NeBRDR_Cnt_LTAP_MFOP_Rx: nv-require-com-spec{init-value=Value:0, variable=NeBRDR_Cnt_LTAP_MFOP}, required-interface=NeBRDR_Cnt_LTAP_MFOP
    provide port NeBRDR_Cnt_HeatExPerf_MFOP: nv-provide-com-spec{ram-block-init-value=Value:0, rom-block-init-value=Value:0, variable=NeBRDR_Cnt_HeatExPerf_MFOP}, provided-interface=NeBRDR_Cnt_HeatExPerf_MFOP
    require port NeBRDR_Cnt_HeatExPerf_MFOP_Rx: nv-require-com-spec{init-value=Value:0, variable=NeBRDR_Cnt_HeatExPerf_MFOP}, required-interface=NeBRDR_Cnt_HeatExPerf_MFOP
    provide port NeBRDR_Cnt_HV_BTOS_MFOP: nv-provide-com-spec{ram-block-init-value=Value:0, rom-block-init-value=Value:0, variable=NeBRDR_Cnt_HV_BTOS_MFOP}, provided-interface=NeBRDR_Cnt_HV_BTOS_MFOP
    require port NeBRDR_Cnt_HV_BTOS_MFOP_Rx: nv-require-com-spec{init-value=Value:0, variable=NeBRDR_Cnt_HV_BTOS_MFOP}, required-interface=NeBRDR_Cnt_HV_BTOS_MFOP
    provide port NeBRDR_Cnt_HV_BTOS2_MFOP: nv-provide-com-spec{ram-block-init-value=Value:0, rom-block-init-value=Value:0, variable=NeBRDR_Cnt_HV_BTOS2_MFOP}, provided-interface=NeBRDR_Cnt_HV_BTOS2_MFOP
    require port NeBRDR_Cnt_HV_BTOS2_MFOP_Rx: nv-require-com-spec{init-value=Value:0, variable=NeBRDR_Cnt_HV_BTOS2_MFOP}, required-interface=NeBRDR_Cnt_HV_BTOS2_MFOP
    provide port NeBRDR_Cnt_HV_BTIS_MFOP: nv-provide-com-spec{ram-block-init-value=Value:0, rom-block-init-value=Value:0, variable=NeBRDR_Cnt_HV_BTIS_MFOP}, provided-interface=NeBRDR_Cnt_HV_BTIS_MFOP
    require port NeBRDR_Cnt_HV_BTIS_MFOP_Rx: nv-require-com-spec{init-value=Value:0, variable=NeBRDR_Cnt_HV_BTIS_MFOP}, required-interface=NeBRDR_Cnt_HV_BTIS_MFOP
    provide port NeBRDR_Cnt_HV_BTIS2_MFOP: nv-provide-com-spec{ram-block-init-value=Value:0, rom-block-init-value=Value:0, variable=NeBRDR_Cnt_HV_BTIS2_MFOP}, provided-interface=NeBRDR_Cnt_HV_BTIS2_MFOP
    require port NeBRDR_Cnt_HV_BTIS2_MFOP_Rx: nv-require-com-spec{init-value=Value:0, variable=NeBRDR_Cnt_HV_BTIS2_MFOP}, required-interface=NeBRDR_Cnt_HV_BTIS2_MFOP
    provide port NeBRDR_Cnt_HV_BHOS_MFOP: nv-provide-com-spec{ram-block-init-value=Value:0, rom-block-init-value=Value:0, variable=NeBRDR_Cnt_HV_BHOS_MFOP}, provided-interface=NeBRDR_Cnt_HV_BHOS_MFOP
    require port NeBRDR_Cnt_HV_BHOS_MFOP_Rx: nv-require-com-spec{init-value=Value:0, variable=NeBRDR_Cnt_HV_BHOS_MFOP}, required-interface=NeBRDR_Cnt_HV_BHOS_MFOP
    provide port NeBRDR_Cnt_HVBatCltLvlSnsCkt_MFOP: nv-provide-com-spec{ram-block-init-value=Value:0, rom-block-init-value=Value:0, variable=NeBRDR_Cnt_HVBatCltLvlSnsCkt_MFOP}, provided-interface=NeBRDR_Cnt_HVBatCltLvlSnsCkt_MFOP
    require port NeBRDR_Cnt_HVBatCltLvlSnsCkt_MFOP_Rx: nv-require-com-spec{init-value=Value:0, variable=NeBRDR_Cnt_HVBatCltLvlSnsCkt_MFOP}, required-interface=NeBRDR_Cnt_HVBatCltLvlSnsCkt_MFOP
    provide port NeBRDR_Cnt_HVBatCltLvLo_OC_MFOP: nv-provide-com-spec{ram-block-init-value=Value:0, rom-block-init-value=Value:0, variable=NeBRDR_Cnt_HVBatCltLvLo_OC_MFOP}, provided-interface=NeBRDR_Cnt_HVBatCltLvLo_OC_MFOP
    require port NeBRDR_Cnt_HVBatCltLvLo_OC_MFOP_Rx: nv-require-com-spec{init-value=Value:0, variable=NeBRDR_Cnt_HVBatCltLvLo_OC_MFOP}, required-interface=NeBRDR_Cnt_HVBatCltLvLo_OC_MFOP
    provide port NeBRDR_Cnt_ChillPerf_MFOP: nv-provide-com-spec{ram-block-init-value=Value:0, rom-block-init-value=Value:0, variable=NeBRDR_Cnt_ChillPerf_MFOP}, provided-interface=NeBRDR_Cnt_ChillPerf_MFOP
    require port NeBRDR_Cnt_ChillPerf_MFOP_Rx: nv-require-com-spec{init-value=Value:0, variable=NeBRDR_Cnt_ChillPerf_MFOP}, required-interface=NeBRDR_Cnt_ChillPerf_MFOP
    provide port NeHVTR_Cnt_AntiTampCounter: nv-provide-com-spec{ram-block-init-value=Value:65535, rom-block-init-value=Value:65535, variable=NeHVTR_Cnt_AntiTampCounter}, provided-interface=NeHVTR_Cnt_AntiTampCounter
    require port NeHVTR_Cnt_AntiTampCounter_Rx: nv-require-com-spec{init-value=Value:65535, variable=NeHVTR_Cnt_AntiTampCounter}, required-interface=NeHVTR_Cnt_AntiTampCounter
    provide port NeHSWD_Cnt_CBC_Range_MFOP: nv-provide-com-spec{ram-block-init-value=Value:0, rom-block-init-value=Value:0, variable=NeHSWD_Cnt_CBC_Range_MFOP}, provided-interface=NeHSWD_Cnt_CBC_Range_MFOP
    require port NeHSWD_Cnt_CBC_Range_MFOP_Rx: nv-require-com-spec{init-value=Value:0, variable=NeHSWD_Cnt_CBC_Range_MFOP}, required-interface=NeHSWD_Cnt_CBC_Range_MFOP
    provide port NeITIR_Cnt_TimeSinceEngineStrt: nv-provide-com-spec{ram-block-init-value=Value:0, rom-block-init-value=Value:0, variable=NeITIR_Cnt_TimeSinceEngineStrt}, provided-interface=NeITIR_Cnt_TimeSinceEngineStrt
    require port NeITIR_Cnt_TimeSinceEngineStrt_Rx: nv-require-com-spec{init-value=Value:0, variable=NeITIR_Cnt_TimeSinceEngineStrt}, required-interface=NeITIR_Cnt_TimeSinceEngineStrt
    provide port NeIMPR_Cnt_HVShtDwn_MFOP: nv-provide-com-spec{ram-block-init-value=Value:0, rom-block-init-value=Value:0, variable=NeIMPR_Cnt_HVShtDwn_MFOP}, provided-interface=NeIMPR_Cnt_HVShtDwn_MFOP
    require port NeIMPR_Cnt_HVShtDwn_MFOP_Rx: nv-require-com-spec{init-value=Value:0, variable=NeIMPR_Cnt_HVShtDwn_MFOP}, required-interface=NeIMPR_Cnt_HVShtDwn_MFOP
    provide port NeCCCR_b_FirstIncrFlag_MinHot: nv-provide-com-spec{ram-block-init-value=Value:0, rom-block-init-value=Value:0, variable=NeCCCR_b_FirstIncrFlag_MinHot}, provided-interface=NeCCCR_b_FirstIncrFlag_MinHot
    require port NeCCCR_b_FirstIncrFlag_MinHot_Rx: nv-require-com-spec{init-value=Value:0, variable=NeCCCR_b_FirstIncrFlag_MinHot}, required-interface=NeCCCR_b_FirstIncrFlag_MinHot
    provide port NeCITR_b_PortLockBCM_Cmd: nv-provide-com-spec{ram-block-init-value=Value:0, rom-block-init-value=Value:0, variable=NeCITR_b_PortLockBCM_Cmd}, provided-interface=NeCITR_b_PortLockBCM_Cmd
    require port NeCITR_b_PortLockBCM_Cmd_Rx: nv-require-com-spec{init-value=Value:0, variable=NeCITR_b_PortLockBCM_Cmd}, required-interface=NeCITR_b_PortLockBCM_Cmd
    provide port NeCITR_b_Lock_Status: nv-provide-com-spec{ram-block-init-value=Value:0, rom-block-init-value=Value:0, variable=NeCITR_b_Lock_Status}, provided-interface=NeCITR_b_Lock_Status
    require port NeCITR_b_Lock_Status_Rx: nv-require-com-spec{init-value=Value:0, variable=NeCITR_b_Lock_Status}, required-interface=NeCITR_b_Lock_Status
    provide port NeCCCR_e_PwrLvlSet: nv-provide-com-spec{ram-block-init-value=Value:0, rom-block-init-value=Value:0, variable=NeCCCR_e_PwrLvlSet}, provided-interface=NeCCCR_e_PwrLvlSet
    require port NeCCCR_e_PwrLvlSet_Rx: nv-require-com-spec{init-value=Value:0, variable=NeCCCR_e_PwrLvlSet}, required-interface=NeCCCR_e_PwrLvlSet
    provide port NeDMIR_e_PddlMdStatus: nv-provide-com-spec{ram-block-init-value=Value:0, rom-block-init-value=Value:0, variable=NeDMIR_e_PddlMdStatus}, provided-interface=NeDMIR_e_PddlMdStatus
    require port NeDMIR_e_PddlMdStatus_Rx: nv-require-com-spec{init-value=Value:0, variable=NeDMIR_e_PddlMdStatus}, required-interface=NeDMIR_e_PddlMdStatus
    provide port NeDMIR_e_CreepSts: nv-provide-com-spec{ram-block-init-value=Value:0, rom-block-init-value=Value:0, variable=NeDMIR_e_CreepSts}, provided-interface=NeDMIR_e_CreepSts
    require port NeDMIR_e_CreepSts_Rx: nv-require-com-spec{init-value=Value:0, variable=NeDMIR_e_CreepSts}, required-interface=NeDMIR_e_CreepSts
    provide port NeCSVR_e_MIL_LightRequest: nv-provide-com-spec{ram-block-init-value=Value:255, rom-block-init-value=Value:255, variable=NeCSVR_e_MIL_LightRequest}, provided-interface=NeCSVR_e_MIL_LightRequest
    require port NeCSVR_e_MIL_LightRequest_Rx: nv-require-com-spec{init-value=Value:255, variable=NeCSVR_e_MIL_LightRequest}, required-interface=NeCSVR_e_MIL_LightRequest
    provide port NeSSDC_b_HVBatPerWU12VChrg: nv-provide-com-spec{ram-block-init-value=Value:0, rom-block-init-value=Value:0, variable=NeSSDC_b_HVBatPerWU12VChrg}, provided-interface=NeSSDC_b_HVBatPerWU12VChrg
    require port NeSSDC_b_HVBatPerWU12VChrg_Rx: nv-require-com-spec{init-value=Value:0, variable=NeSSDC_b_HVBatPerWU12VChrg}, required-interface=NeSSDC_b_HVBatPerWU12VChrg
    provide port NeSSDC_b_HVBatPerWUCabinPre: nv-provide-com-spec{ram-block-init-value=Value:0, rom-block-init-value=Value:0, variable=NeSSDC_b_HVBatPerWUCabinPre}, provided-interface=NeSSDC_b_HVBatPerWUCabinPre
    require port NeSSDC_b_HVBatPerWUCabinPre_Rx: nv-require-com-spec{init-value=Value:0, variable=NeSSDC_b_HVBatPerWUCabinPre}, required-interface=NeSSDC_b_HVBatPerWUCabinPre
    provide port NeSSDC_b_HVBatPerWUSchChrg: nv-provide-com-spec{ram-block-init-value=Value:0, rom-block-init-value=Value:0, variable=NeSSDC_b_HVBatPerWUSchChrg}, provided-interface=NeSSDC_b_HVBatPerWUSchChrg
    require port NeSSDC_b_HVBatPerWUSchChrg_Rx: nv-require-com-spec{init-value=Value:0, variable=NeSSDC_b_HVBatPerWUSchChrg}, required-interface=NeSSDC_b_HVBatPerWUSchChrg
    provide port NeSSDC_b_HVBatPerWUThermal: nv-provide-com-spec{ram-block-init-value=Value:0, rom-block-init-value=Value:0, variable=NeSSDC_b_HVBatPerWUThermal}, provided-interface=NeSSDC_b_HVBatPerWUThermal
    require port NeSSDC_b_HVBatPerWUThermal_Rx: nv-require-com-spec{init-value=Value:0, variable=NeSSDC_b_HVBatPerWUThermal}, required-interface=NeSSDC_b_HVBatPerWUThermal
    provide port NeCSVR_b_PriorMIL_StatusOn: nv-provide-com-spec{ram-block-init-value=Value:1, rom-block-init-value=Value:1, variable=NeCSVR_b_PriorMIL_StatusOn}, provided-interface=NeCSVR_b_PriorMIL_StatusOn
    require port NeCSVR_b_PriorMIL_StatusOn_Rx: nv-require-com-spec{init-value=Value:1, variable=NeCSVR_b_PriorMIL_StatusOn}, required-interface=NeCSVR_b_PriorMIL_StatusOn
    provide port NeCPLR_e_RemoteLockLastSts: nv-provide-com-spec{ram-block-init-value=Value:0, rom-block-init-value=Value:0, variable=NeCPLR_e_RemoteLockLastSts}, provided-interface=NeCPLR_e_RemoteLockLastSts
    require port NeCPLR_e_RemoteLockLastSts_Rx: nv-require-com-spec{init-value=Value:0, variable=NeCPLR_e_RemoteLockLastSts}, required-interface=NeCPLR_e_RemoteLockLastSts
    provide port NeCPLR_e_DoorLastSts: nv-provide-com-spec{ram-block-init-value=Value:0, rom-block-init-value=Value:0, variable=NeCPLR_e_DoorLastSts}, provided-interface=NeCPLR_e_DoorLastSts
    require port NeCPLR_e_DoorLastSts_Rx: nv-require-com-spec{init-value=Value:0, variable=NeCPLR_e_DoorLastSts}, required-interface=NeCPLR_e_DoorLastSts
    provide port NeCPLR_e_ChargeportLockLastSts: nv-provide-com-spec{ram-block-init-value=Value:0, rom-block-init-value=Value:0, variable=NeCPLR_e_ChargeportLockLastSts}, provided-interface=NeCPLR_e_ChargeportLockLastSts
    require port NeCPLR_e_ChargeportLockLastSts_Rx: nv-require-com-spec{init-value=Value:0, variable=NeCPLR_e_ChargeportLockLastSts}, required-interface=NeCPLR_e_ChargeportLockLastSts
    provide port NeCPLR_b_ManualRelease: nv-provide-com-spec{ram-block-init-value=Value:0, rom-block-init-value=Value:0, variable=NeCPLR_b_ManualRelease}, provided-interface=NeCPLR_b_ManualRelease
    require port NeCPLR_b_ManualRelease_Rx: nv-require-com-spec{init-value=Value:0, variable=NeCPLR_b_ManualRelease}, required-interface=NeCPLR_b_ManualRelease
    provide port NeCCCR_b_FirstIncrFlag_MaxHot: nv-provide-com-spec{ram-block-init-value=Value:0, rom-block-init-value=Value:0, variable=NeCCCR_b_FirstIncrFlag_MaxHot}, provided-interface=NeCCCR_b_FirstIncrFlag_MaxHot
    require port NeCCCR_b_FirstIncrFlag_MaxHot_Rx: nv-require-com-spec{init-value=Value:0, variable=NeCCCR_b_FirstIncrFlag_MaxHot}, required-interface=NeCCCR_b_FirstIncrFlag_MaxHot
    provide port NeCCCR_b_FirstIncrFlag_MinCold: nv-provide-com-spec{ram-block-init-value=Value:0, rom-block-init-value=Value:0, variable=NeCCCR_b_FirstIncrFlag_MinCold}, provided-interface=NeCCCR_b_FirstIncrFlag_MinCold
    require port NeCCCR_b_FirstIncrFlag_MinCold_Rx: nv-require-com-spec{init-value=Value:0, variable=NeCCCR_b_FirstIncrFlag_MinCold}, required-interface=NeCCCR_b_FirstIncrFlag_MinCold
    provide port NeCCCR_b_FirstIncrFlag_Cold: nv-provide-com-spec{ram-block-init-value=Value:0, rom-block-init-value=Value:0, variable=NeCCCR_b_FirstIncrFlag_Cold}, provided-interface=NeCCCR_b_FirstIncrFlag_Cold
    require port NeCCCR_b_FirstIncrFlag_Cold_Rx: nv-require-com-spec{init-value=Value:0, variable=NeCCCR_b_FirstIncrFlag_Cold}, required-interface=NeCCCR_b_FirstIncrFlag_Cold
    provide port NeCCCR_b_FirstIncrFlag_MaxCold: nv-provide-com-spec{ram-block-init-value=Value:0, rom-block-init-value=Value:0, variable=NeCCCR_b_FirstIncrFlag_MaxCold}, provided-interface=NeCCCR_b_FirstIncrFlag_MaxCold
    require port NeCCCR_b_FirstIncrFlag_MaxCold_Rx: nv-require-com-spec{init-value=Value:0, variable=NeCCCR_b_FirstIncrFlag_MaxCold}, required-interface=NeCCCR_b_FirstIncrFlag_MaxCold
    provide port NeAECR_e_eCoastLvlLatched: nv-provide-com-spec{ram-block-init-value=Value:0, rom-block-init-value=Value:0, variable=NeAECR_e_eCoastLvlLatched}, provided-interface=NeAECR_e_eCoastLvlLatched
    require port NeAECR_e_eCoastLvlLatched_Rx: nv-require-com-spec{init-value=Value:0, variable=NeAECR_e_eCoastLvlLatched}, required-interface=NeAECR_e_eCoastLvlLatched
    provide port NeAECR_e_eCoastDefaultCustom: nv-provide-com-spec{ram-block-init-value=Value:0, rom-block-init-value=Value:0, variable=NeAECR_e_eCoastDefaultCustom}, provided-interface=NeAECR_e_eCoastDefaultCustom
    require port NeAECR_e_eCoastDefaultCustom_Rx: nv-require-com-spec{init-value=Value:0, variable=NeAECR_e_eCoastDefaultCustom}, required-interface=NeAECR_e_eCoastDefaultCustom
    provide port NeAECR_e_eCoastDefaultAuto: nv-provide-com-spec{ram-block-init-value=Value:0, rom-block-init-value=Value:0, variable=NeAECR_e_eCoastDefaultAuto}, provided-interface=NeAECR_e_eCoastDefaultAuto
    require port NeAECR_e_eCoastDefaultAuto_Rx: nv-require-com-spec{init-value=Value:0, variable=NeAECR_e_eCoastDefaultAuto}, required-interface=NeAECR_e_eCoastDefaultAuto
    provide port NeAECR_e_RegenSts: nv-provide-com-spec{ram-block-init-value=Value:0, rom-block-init-value=Value:0, variable=NeAECR_e_RegenSts}, provided-interface=NeAECR_e_RegenSts
    require port NeAECR_e_RegenSts_Rx: nv-require-com-spec{init-value=Value:0, variable=NeAECR_e_RegenSts}, required-interface=NeAECR_e_RegenSts
    provide port NeAECR_e_RaceModeSts: nv-provide-com-spec{ram-block-init-value=Value:0, rom-block-init-value=Value:0, variable=NeAECR_e_RaceModeSts}, provided-interface=NeAECR_e_RaceModeSts
